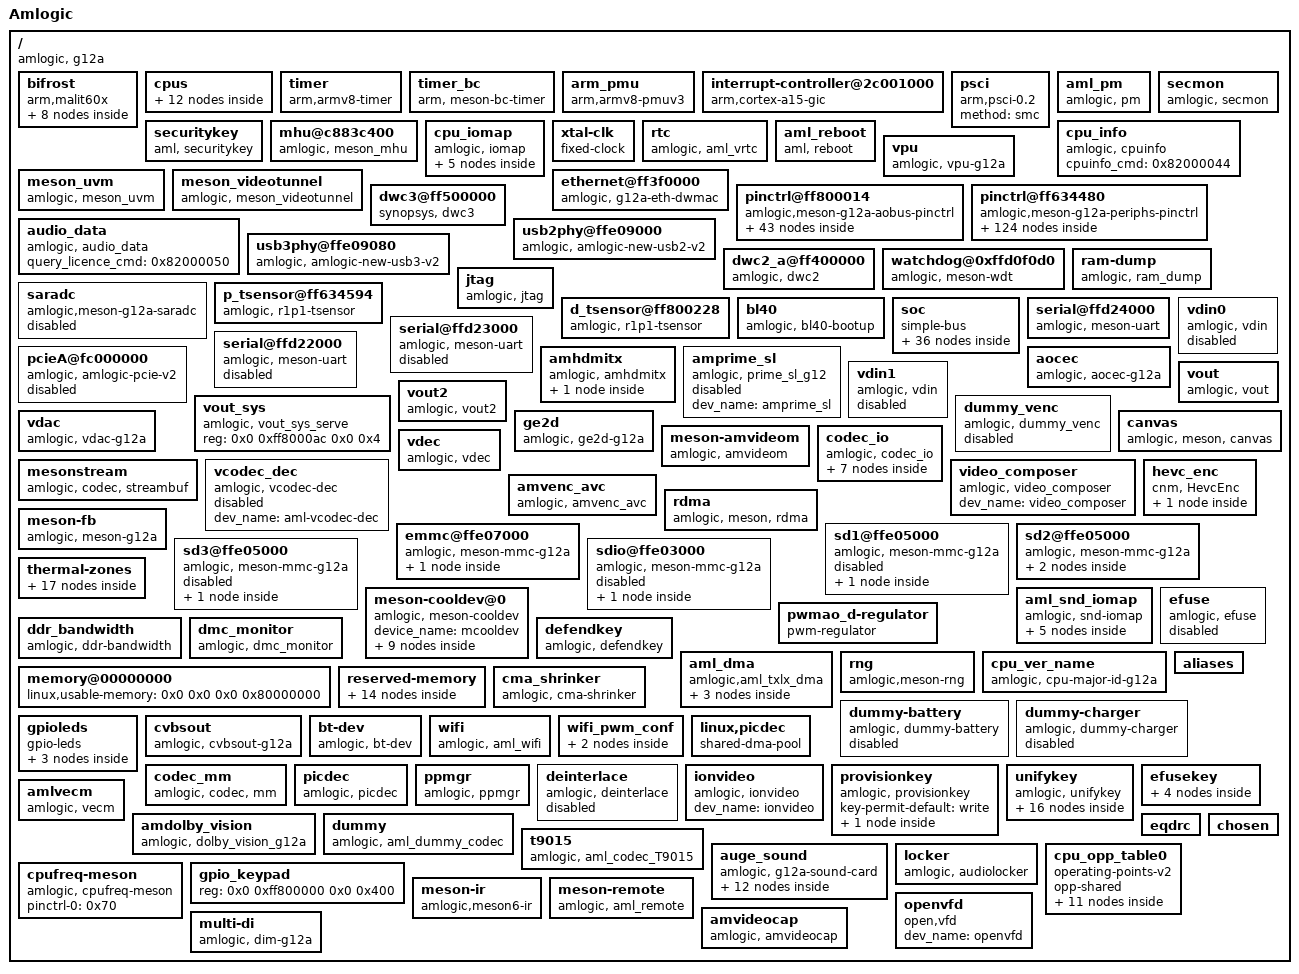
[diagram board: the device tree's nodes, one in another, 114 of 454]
/dts-v1/;

/ {
	model = "Amlogic";
	compatible = "amlogic, g12a";
	interrupt-parent = <0x1>;
	#address-cells = <0x2>;
	#size-cells = <0x2>;
	coreelec;
	coreelec-dt-id = "g12a_s905x2_2g";

	bifrost {
		compatible = "arm,malit60x", "arm,malit6xx", "arm,mali-midgard";
		#cooling-cells = <0x2>;
		reg = <0x0 0xffe40000 0x0 0x4000 0x0 0xffd01000 0x0 0x1000 0x0 0xff800000 0x0 0x1000 0x0 0xff63c000 0x0 0x1000 0x0 0xffd01000 0x0 0x1000>;
		interrupt-parent = <0x1>;
		interrupts = <0x0 0xa0 0x4 0x0 0xa1 0x4 0x0 0xa2 0x4>;
		interrupt-names = "GPU", "MMU", "JOB";
		num_of_pp = <0x2>;
		sc_mpp = <0x1>;
		clocks = <0x2 0x84 0x2 0x7>;
		clock-names = "gpu_mux", "gp0_pll";
		tbl = <0x3 0x4 0x5 0x6 0x7 0x7>;
		phandle = <0x72>;

		clk125_cfg {
			clk_freq = <0x7735940>;
			clk_parent = "fclk_div4";
			clkp_freq = <0x1dcd6500>;
			clk_reg = <0xa03>;
			voltage = <0x47e>;
			keep_count = <0x5>;
			threshold = <0x1e 0x78>;
			phandle = <0x73>;
		};

		dvfs250_cfg {
			clk_freq = <0xee6b280>;
			clk_parent = "fclk_div4";
			clkp_freq = <0x1dcd6500>;
			clk_reg = <0xa01>;
			voltage = <0x47e>;
			keep_count = <0x5>;
			threshold = <0x50 0xaa>;
			phandle = <0x74>;
		};

		dvfs285_cfg {
			clk_freq = <0x1107a76d>;
			clk_parent = "fclk_div7";
			clkp_freq = <0x1107a76d>;
			clk_reg = <0xe00>;
			voltage = <0x47e>;
			keep_count = <0x5>;
			threshold = <0x0 0x4c>;
			phandle = <0x3>;
		};

		dvfs400_cfg {
			clk_freq = <0x17d78400>;
			clk_parent = "fclk_div5";
			clkp_freq = <0x17d78400>;
			clk_reg = <0xc00>;
			voltage = <0x47e>;
			keep_count = <0x5>;
			threshold = <0x98 0xcf>;
			phandle = <0x4>;
		};

		dvfs500_cfg {
			clk_freq = <0x1dcd6500>;
			clk_parent = "fclk_div4";
			clkp_freq = <0x1dcd6500>;
			clk_reg = <0xa00>;
			voltage = <0x47e>;
			keep_count = <0x5>;
			threshold = <0x26 0xc2>;
			phandle = <0x5>;
		};

		dvfs666_cfg {
			clk_freq = <0x27bc86aa>;
			clk_parent = "fclk_div3";
			clkp_freq = <0x27bc86aa>;
			clk_reg = <0x800>;
			voltage = <0x47e>;
			keep_count = <0x5>;
			threshold = <0x96 0xcb>;
			phandle = <0x6>;
		};

		dvfs800_cfg {
			clk_freq = <0x2faf0800>;
			clk_parent = "fclk_div2p5";
			clkp_freq = <0x2faf0800>;
			clk_reg = <0x600>;
			voltage = <0x47e>;
			keep_count = <0x5>;
			threshold = <0xe6 0xff>;
			phandle = <0x75>;
		};

		dvfs850_cfg {
			clk_freq = <0x326cef80>;
			clk_parent = "gp0_pll";
			clkp_freq = <0x326cef80>;
			clk_reg = <0x200>;
			voltage = <0x47e>;
			keep_count = <0x5>;
			threshold = <0x9c 0xff>;
			phandle = <0x7>;
		};
	};

	cpus {
		#address-cells = <0x2>;
		#size-cells = <0x0>;
		phandle = <0x76>;

		cpu-map {

			cluster0 {
				phandle = <0x77>;

				core0 {
					cpu = <0x8>;
				};

				core1 {
					cpu = <0x9>;
				};

				core2 {
					cpu = <0xa>;
				};

				core3 {
					cpu = <0xb>;
				};
			};
		};

		cpu@0 {
			device_type = "cpu";
			compatible = "arm,cortex-a53", "arm,armv8";
			reg = <0x0 0x0>;
			enable-method = "psci";
			cpu-idle-states = <0xc>;
			clocks = <0x2 0x17 0x2 0x16 0x2 0x0>;
			clock-names = "core_clk", "low_freq_clk_parent", "high_freq_clk_parent";
			operating-points-v2 = <0xd>;
			cpu-supply = <0xe>;
			voltage-tolerance = <0x0>;
			clock-latency = <0xc350>;
			phandle = <0x8>;
		};

		cpu@1 {
			device_type = "cpu";
			compatible = "arm,cortex-a53", "arm,armv8";
			reg = <0x0 0x1>;
			enable-method = "psci";
			cpu-idle-states = <0xc>;
			clocks = <0x2 0x17 0x2 0x16 0x2 0x0>;
			clock-names = "core_clk", "low_freq_clk_parent", "high_freq_clk_parent";
			operating-points-v2 = <0xd>;
			cpu-supply = <0xe>;
			voltage-tolerance = <0x0>;
			clock-latency = <0xc350>;
			phandle = <0x9>;
		};

		cpu@2 {
			device_type = "cpu";
			compatible = "arm,cortex-a53", "arm,armv8";
			reg = <0x0 0x2>;
			enable-method = "psci";
			cpu-idle-states = <0xc>;
			clocks = <0x2 0x17 0x2 0x16 0x2 0x0>;
			clock-names = "core_clk", "low_freq_clk_parent", "high_freq_clk_parent";
			operating-points-v2 = <0xd>;
			cpu-supply = <0xe>;
			voltage-tolerance = <0x0>;
			clock-latency = <0xc350>;
			phandle = <0xa>;
		};

		cpu@3 {
			device_type = "cpu";
			compatible = "arm,cortex-a53", "arm,armv8";
			reg = <0x0 0x3>;
			enable-method = "psci";
			cpu-idle-states = <0xc>;
			clocks = <0x2 0x17 0x2 0x16 0x2 0x0>;
			clock-names = "core_clk", "low_freq_clk_parent", "high_freq_clk_parent";
			operating-points-v2 = <0xd>;
			cpu-supply = <0xe>;
			voltage-tolerance = <0x0>;
			clock-latency = <0xc350>;
			phandle = <0xb>;
		};

		idle-states {
			entry-method = "arm,psci-0.2";

			cpu-sleep-0 {
				compatible = "arm,idle-state";
				arm,psci-suspend-param = <0x10000>;
				local-timer-stop;
				entry-latency-us = <0x1388>;
				exit-latency-us = <0x1388>;
				min-residency-us = <0x3a98>;
				phandle = <0xc>;
			};
		};
	};

	timer {
		compatible = "arm,armv8-timer";
		interrupts = <0x1 0xd 0xff08 0x1 0xe 0xff08 0x1 0xb 0xff08 0x1 0xa 0xff08>;
	};

	timer_bc {
		compatible = "arm, meson-bc-timer";
		reg = <0x0 0xffd0f190 0x0 0x4 0x0 0xffd0f194 0x0 0x4>;
		timer_name = "Meson TimerF";
		clockevent-rating = <0x12c>;
		clockevent-shift = <0x14>;
		clockevent-features = <0x23>;
		interrupts = <0x0 0x3c 0x1>;
		bit_enable = <0x10>;
		bit_mode = <0xc>;
		bit_resolution = <0x0>;
	};

	arm_pmu {
		compatible = "arm,armv8-pmuv3";
		interrupts = <0x0 0x89 0x4>;
		reg = <0x0 0xff634680 0x0 0x4>;
		cpumasks = <0xf>;
		relax-timer-ns = <0x989680>;
		max-wait-cnt = <0x2710>;
	};

	interrupt-controller@2c001000 {
		compatible = "arm,cortex-a15-gic", "arm,cortex-a9-gic";
		#interrupt-cells = <0x3>;
		#address-cells = <0x0>;
		interrupt-controller;
		reg = <0x0 0xffc01000 0x0 0x1000 0x0 0xffc02000 0x0 0x100>;
		interrupts = <0x1 0x9 0xf04>;
		phandle = <0x1>;
	};

	psci {
		compatible = "arm,psci-0.2";
		method = "smc";
	};

	aml_pm {
		compatible = "amlogic, pm";
		status = "okay";
		device_name = "aml_pm";
		debug_reg = <0xff8000a8>;
		exit_reg = <0xff80023c>;
	};

	secmon {
		compatible = "amlogic, secmon";
		memory-region = <0xf>;
		in_base_func = <0x82000020>;
		out_base_func = <0x82000021>;
		reserve_mem_size = <0x300000>;
	};

	securitykey {
		compatible = "aml, securitykey";
		storage_query = <0x82000060>;
		storage_read = <0x82000061>;
		storage_write = <0x82000062>;
		storage_tell = <0x82000063>;
		storage_verify = <0x82000064>;
		storage_status = <0x82000065>;
		storage_list = <0x82000067>;
		storage_remove = <0x82000068>;
		storage_in_func = <0x82000023>;
		storage_out_func = <0x82000024>;
		storage_block_func = <0x82000025>;
		storage_size_func = <0x82000027>;
		storage_set_enctype = <0x8200006a>;
		storage_get_enctype = <0x8200006b>;
		storage_version = <0x8200006c>;
	};

	mhu@c883c400 {
		compatible = "amlogic, meson_mhu";
		reg = <0x0 0xff63c400 0x0 0x4c 0x0 0xfffe7000 0x0 0x800>;
		interrupts = <0x0 0xd1 0x1 0x0 0xd2 0x1 0x0 0xd5 0x1>;
		#mbox-cells = <0x1>;
		mbox-names = "cpu_to_scp_low", "bl4_to_cpu", "cpu_to_bl4";
		mboxes = <0x10 0x0 0x10 0x1 0x10 0x2>;
		num-chans-to-scp = <0x1>;
		send-isr-bits = <0x5>;
		ack-isr-bits = <0x4>;
		m4-isr-bits = <0x6>;
		mbox-chans = <0x3>;
		phandle = <0x10>;
	};

	cpu_iomap {
		compatible = "amlogic, iomap";
		#address-cells = <0x2>;
		#size-cells = <0x2>;
		ranges;

		io_cbus_base {
			reg = <0x0 0xffd00000 0x0 0x26000>;
		};

		io_apb_base {
			reg = <0x0 0xffe01000 0x0 0x7f000>;
		};

		io_aobus_base {
			reg = <0x0 0xff800000 0x0 0xb000>;
		};

		io_vapb_base {
			reg = <0x0 0xff900000 0x0 0x50000>;
		};

		io_hiu_base {
			reg = <0x0 0xff63c000 0x0 0x2000>;
		};
	};

	xtal-clk {
		compatible = "fixed-clock";
		clock-frequency = <0x16e3600>;
		clock-output-names = "xtal";
		#clock-cells = <0x0>;
		phandle = <0x15>;
	};

	rtc {
		compatible = "amlogic, aml_vrtc";
		alarm_reg_addr = <0xff8000a8>;
		timer_e_addr = <0xffd0f188>;
		init_date = "2015/01/01";
		status = "okay";
	};

	cpu_info {
		compatible = "amlogic, cpuinfo";
		status = "okay";
		cpuinfo_cmd = <0x82000044>;
	};

	aml_reboot {
		compatible = "aml, reboot";
		sys_reset = <0x84000009>;
		sys_poweroff = <0x84000008>;
	};

	vpu {
		compatible = "amlogic, vpu-g12a";
		dev_name = "vpu";
		status = "okay";
		clocks = <0x2 0x96 0x2 0x4d 0x2 0x88 0x2 0x8c 0x2 0x8d>;
		clock-names = "vapb_clk", "vpu_intr_gate", "vpu_clk0", "vpu_clk1", "vpu_clk";
		clk_level = <0x7>;
	};

	meson_uvm {
		compatible = "amlogic, meson_uvm";
		status = "okay";
	};

	meson_videotunnel {
		compatible = "amlogic, meson_videotunnel";
		status = "okay";
	};

	ethernet@ff3f0000 {
		compatible = "amlogic, g12a-eth-dwmac", "snps,dwmac";
		reg = <0x0 0xff3f0000 0x0 0x10000 0x0 0xff634540 0x0 0x8 0x0 0xff64c000 0x0 0xa0 0x0 0xffd01008 0x0 0x4>;
		reg-names = "eth_base", "eth_cfg", "eth_pll", "eth_reset";
		interrupts = <0x0 0x8 0x1>;
		interrupt-names = "macirq";
		status = "okay";
		clocks = <0x2 0x39>;
		clock-names = "ethclk81";
		pll_val = <0x9c0040a 0x927e0000 0xac5f49e5>;
		analog_val = <0x20200000 0xc000 0x23>;
		pinctrl-names = "internal_eth_pins", "internal_gpio_pins";
		pinctrl-0 = <0x11>;
		pinctrl-1 = <0x12>;
		mc_val = <0x4be04>;
		internal_phy = <0x1>;
		phandle = <0x78>;
	};

	pinctrl@ff800014 {
		compatible = "amlogic,meson-g12a-aobus-pinctrl";
		#address-cells = <0x2>;
		#size-cells = <0x2>;
		ranges;
		phandle = <0x79>;

		ao-bank@ff800014 {
			reg = <0x0 0xff800014 0x0 0x8 0x0 0xff800024 0x0 0x14 0x0 0xff80001c 0x0 0x8>;
			reg-names = "mux", "gpio", "drive-strength";
			gpio-controller;
			#gpio-cells = <0x2>;
			phandle = <0x4c>;
		};

		sd_to_ao_uart_clr_pins {
			phandle = <0x38>;

			mux {
				groups = "GPIOAO_0", "GPIOAO_1";
				function = "gpio_aobus";
			};
		};

		sd_to_ao_uart_pins {
			phandle = <0x3a>;

			mux {
				groups = "uart_ao_tx_a", "uart_ao_rx_a";
				function = "uart_ao_a";
				bias-pull-up;
				input-enable;
			};
		};

		ao_uart {
			phandle = <0x7a>;

			mux {
				groups = "uart_ao_tx_a", "uart_ao_rx_a";
				function = "uart_ao_a";
			};
		};

		ao_b_uart {
			phandle = <0x1b>;

			mux {
				groups = "uart_ao_tx_b_2", "uart_ao_rx_b_3";
				function = "uart_ao_b";
			};
		};

		ao_i2c_pins1 {
			phandle = <0x7b>;

			mux {
				groups = "i2c_ao_sck", "i2c_ao_sda";
				function = "i2c_ao";
				drive-strength = <0x2>;
			};
		};

		ao_i2c_pins2 {
			phandle = <0x7c>;

			mux {
				groups = "i2c_ao_sck_e", "i2c_ao_sda_e";
				function = "i2c_ao";
				drive-strength = <0x2>;
			};
		};

		ao_i2c_slave_pins {
			phandle = <0x1a>;

			mux {
				groups = "i2c_ao_slave_sck", "i2c_ao_slave_sda";
				function = "i2c_ao_slave";
			};
		};

		pwm_ao_a {
			phandle = <0x7d>;

			mux {
				groups = "pwm_ao_a";
				function = "pwm_ao_a";
			};
		};

		pwm_ao_a_hiz {
			phandle = <0x7e>;

			mux {
				groups = "pwm_ao_a_hiz";
				function = "pwm_ao_a";
			};
		};

		pwm_ao_b {
			phandle = <0x7f>;

			mux {
				groups = "pwm_ao_b";
				function = "pwm_ao_b";
			};
		};

		pwm_ao_c_pins1 {
			phandle = <0x80>;

			mux {
				groups = "pwm_ao_c_4";
				function = "pwm_ao_c";
			};
		};

		pwm_ao_c_pins2 {
			phandle = <0x81>;

			mux {
				groups = "pwm_ao_c_6";
				function = "pwm_ao_c";
			};
		};

		pwm_ao_c_hiz {
			phandle = <0x82>;

			mux {
				groups = "pwm_ao_c_hiz_4";
				function = "pwm_ao_c";
			};
		};

		pwm_ao_d_pins1 {
			phandle = <0x83>;

			mux {
				groups = "pwm_ao_d_5";
				function = "pwm_ao_d";
			};
		};

		pwm_ao_d_pins2 {
			phandle = <0x84>;

			mux {
				groups = "pwm_ao_d_10";
				function = "pwm_ao_d";
			};
		};

		pwm_ao_d_pins3 {
			phandle = <0x70>;

			mux {
				groups = "pwm_ao_d_e";
				function = "pwm_ao_d";
			};
		};

		ao_ceca {
			phandle = <0x85>;

			mux {
				groups = "cec_ao_a";
				function = "cec_ao";
			};
		};

		ao_cecb {
			phandle = <0x86>;

			mux {
				groups = "cec_ao_b";
				function = "cec_ao";
			};
		};

		jtag_apao_pin {
			phandle = <0x16>;

			mux {
				groups = "jtag_a_tdi", "jtag_a_tdo", "jtag_a_clk", "jtag_a_tms";
				function = "jtag_a";
			};
		};

		remote_pin {
			phandle = <0x71>;

			mux {
				groups = "remote_input_ao";
				function = "remote_input_ao";
			};
		};

		irblaster_pin {
			phandle = <0x1c>;

			mux {
				groups = "remote_out_ao";
				function = "remote_out_ao";
			};
		};
	};

	pinctrl@ff634480 {
		compatible = "amlogic,meson-g12a-periphs-pinctrl";
		#address-cells = <0x2>;
		#size-cells = <0x2>;
		ranges;
		phandle = <0x87>;

		banks@ff6346c0 {
			reg = <0x0 0xff6346c0 0x0 0x40 0x0 0xff6344e8 0x0 0x18 0x0 0xff634520 0x0 0x18 0x0 0xff634440 0x0 0x4c 0x0 0xff634740 0x0 0x1c>;
			reg-names = "mux", "pull", "pull-enable", "gpio", "drive-strength";
			gpio-controller;
			#gpio-cells = <0x2>;
			phandle = <0x28>;
		};

		emmc_clk_cmd_pins {
			phandle = <0x32>;

			mux {
				groups = "emmc_clk", "emmc_cmd";
				function = "emmc";
				input-enable;
				bias-pull-up;
			};
		};

		emmc_conf_pull_up {
			phandle = <0x33>;

			mux {
				groups = "emmc_nand_d7", "emmc_nand_d6", "emmc_nand_d5", "emmc_nand_d4", "emmc_nand_d3", "emmc_nand_d2", "emmc_nand_d1", "emmc_nand_d0", "emmc_clk", "emmc_cmd";
				function = "emmc";
				input-enable;
				bias-pull-up;
			};
		};

		emmc_conf_pull_done {
			phandle = <0x34>;

			mux {
				groups = "emmc_nand_ds";
				function = "emmc";
				input-enable;
				bias-pull-down;
			};
		};

		sd_clk_cmd_pins {
			phandle = <0x36>;

			mux {
				groups = "sdcard_cmd_c";
				function = "sdcard";
				input-enable;
				bias-pull-up;
				drive-strength = <0x3>;
			};

			mux1 {
				groups = "sdcard_clk_c";
				function = "sdcard";
				bias-pull-up;
				output-high;
				drive-strength = <0x3>;
			};
		};

		sd_all_pins {
			phandle = <0x35>;

			mux {
				groups = "sdcard_d0_c", "sdcard_d1_c", "sdcard_d2_c", "sdcard_d3_c", "sdcard_cmd_c";
				function = "sdcard";
				input-enable;
				bias-pull-up;
				drive-strength = <0x3>;
			};

			mux1 {
				groups = "sdcard_clk_c";
				function = "sdcard";
				bias-pull-up;
				output-high;
				drive-strength = <0x3>;
			};
		};

		sd_1bit_pins {
			phandle = <0x37>;

			mux {
				groups = "sdcard_d0_c", "sdcard_cmd_c";
				function = "sdcard";
				input-enable;
				bias-pull-up;
				drive-strength = <0x3>;
			};

			mux1 {
				groups = "sdcard_clk_c";
				function = "sdcard";
				bias-pull-up;
				output-high;
				drive-strength = <0x3>;
			};
		};

		sd_clr_all_pins {
			phandle = <0x3e>;

			mux {
				groups = "GPIOC_0", "GPIOC_1", "GPIOC_2", "GPIOC_3", "GPIOC_5";
				function = "gpio_periphs";
				output-high;
			};

			mux1 {
				groups = "GPIOC_4";
				function = "gpio_periphs";
				output-low;
			};
		};

		sd_clr_noall_pins {
			phandle = <0x3d>;

			mux {
				groups = "GPIOC_0", "GPIOC_1", "GPIOC_4", "GPIOC_5";
				function = "gpio_periphs";
				output-high;
			};
		};

		ao_to_sd_uart_pins {
			phandle = <0x39>;

			mux {
				groups = "uart_ao_tx_a_c3", "uart_ao_rx_a_c2";
				function = "uart_ao_a_ee";
				bias-pull-up;
				input-enable;
			};
		};

		sdio_clk_cmd_pins {
			phandle = <0x42>;

			mux {
				groups = "sdio_clk", "sdio_cmd";
				function = "sdio";
				input-enable;
				bias-pull-up;
				drive-strength = <0x3>;
			};
		};

		sdio_all_pins {
			phandle = <0x41>;

			mux {
				groups = "sdio_d0", "sdio_d1", "sdio_d2", "sdio_d3", "sdio_clk", "sdio_cmd";
				function = "sdio";
				input-enable;
				bias-pull-up;
				drive-strength = <0x3>;
			};
		};

		sdio_x_clk_cmd_pins {
			phandle = <0x40>;

			mux {
				groups = "GPIOX_5";
				function = "gpio_periphs";
				input-enable;
				bias-pull-up;
				drive-strength = <0x3>;
			};

			mux1 {
				groups = "GPIOX_4";
				function = "gpio_periphs";
				bias-pull-up;
				output-high;
				drive-strength = <0x3>;
			};
		};

		sdio_x_all_pins {
			phandle = <0x3f>;

			mux {
				groups = "GPIOX_0", "GPIOX_1", "GPIOX_2", "GPIOX_3", "GPIOX_5";
				function = "gpio_periphs";
				input-enable;
				bias-pull-up;
				drive-strength = <0x3>;
			};

			mux1 {
				groups = "GPIOX_4";
				function = "gpio_periphs";
				bias-pull-up;
				output-high;
				drive-strength = <0x3>;
			};
		};

		sdio_x_en_pins {
			phandle = <0x3c>;

			mux {
				groups = "sdio_dummy";
				function = "sdio";
				bias-pull-up;
				output-high;
			};
		};

		sdio_x_clr_pins {
			phandle = <0x3b>;

			mux {
				groups = "GPIOV_0";
				function = "gpio_periphs";
				bias-pull-up;
				output-low;
			};

			mux1 {
				groups = "GPIOX_4";
				function = "gpio_periphs";
				output-low;
			};
		};

		all_nand_pins {
			phandle = <0x88>;

			mux {
				groups = "emmc_nand_d0", "emmc_nand_d1", "emmc_nand_d2", "emmc_nand_d3", "emmc_nand_d4", "emmc_nand_d5", "emmc_nand_d6", "emmc_nand_d7", "nand_ce0", "nand_ale", "nand_cle", "nand_wen_clk", "nand_ren_wr", "nand_rb0";
				function = "nand";
				input-enable;
			};
		};

		nand_cs {
			phandle = <0x89>;

			mux {
				groups = "nand_ce0";
				function = "nand";
			};
		};

		i2c0_pins1 {
			phandle = <0x8a>;

			mux {
				groups = "i2c0_sda_c", "i2c0_sck_c";
				function = "i2c0";
				drive-strength = <0x2>;
			};
		};

		i2c0_pins2 {
			phandle = <0x18>;

			mux {
				groups = "i2c0_sda_z0", "i2c0_sck_z1";
				function = "i2c0";
				drive-strength = <0x2>;
			};
		};

		i2c0_pins3 {
			phandle = <0x8b>;

			mux {
				groups = "i2c0_sda_z7", "i2c0_sck_z8";
				function = "i2c0";
				drive-strength = <0x2>;
			};
		};

		i2c1_pins1 {
			phandle = <0x8c>;

			mux {
				groups = "i2c1_sda_x", "i2c1_sck_x";
				function = "i2c1";
				drive-strength = <0x2>;
			};
		};

		i2c1_pins2 {
			phandle = <0x8d>;

			mux {
				groups = "i2c1_sda_h2", "i2c1_sck_h3";
				function = "i2c1";
				drive-strength = <0x2>;
			};
		};

		i2c1_pins3 {
			phandle = <0x8e>;

			mux {
				groups = "i2c1_sda_h6", "i2c1_sck_h7";
				function = "i2c1";
				drive-strength = <0x2>;
			};
		};

		i2c2_pins1 {
			phandle = <0x8f>;

			mux {
				groups = "i2c2_sda_x", "i2c2_sck_x";
				function = "i2c2";
				drive-strength = <0x2>;
			};
		};

		i2c2_pins2 {
			phandle = <0x90>;

			mux {
				groups = "i2c2_sda_z", "i2c2_sck_z";
				function = "i2c2";
				drive-strength = <0x2>;
			};
		};

		i2c3_pins1 {
			phandle = <0x2d>;

			mux {
				groups = "i2c3_sda_h", "i2c3_sck_h";
				function = "i2c3";
				drive-strength = <0x2>;
			};
		};

		i2c3_pins2 {
			phandle = <0x19>;

			mux {
				groups = "i2c3_sda_a", "i2c3_sck_a";
				function = "i2c3";
				drive-strength = <0x2>;
			};
		};

		pwm_a {
			phandle = <0x91>;

			mux {
				groups = "pwm_a";
				function = "pwm_a";
			};
		};

		pwm_b_pins1 {
			phandle = <0x92>;

			mux {
				groups = "pwm_b_x7";
				function = "pwm_b";
			};
		};

		pwm_b_pins2 {
			phandle = <0x93>;

			mux {
				groups = "pwm_b_x19";
				function = "pwm_b";
			};
		};

		pwm_c_pins1 {
			phandle = <0x94>;

			mux {
				groups = "pwm_c_c4";
				function = "pwm_c";
			};
		};

		pwm_c_pins2 {
			phandle = <0x95>;

			mux {
				groups = "pwm_c_x5";
				function = "pwm_c";
			};
		};

		pwm_c_pins3 {
			phandle = <0x96>;

			mux {
				groups = "pwm_c_x8";
				function = "pwm_c";
			};
		};

		pwm_d_pins1 {
			phandle = <0x97>;

			mux {
				groups = "pwm_d_x3";
				function = "pwm_d";
			};
		};

		pwm_d_pins2 {
			phandle = <0x98>;

			mux {
				groups = "pwm_d_x6";
				function = "pwm_d";
			};
		};

		pwm_e {
			phandle = <0x4d>;

			mux {
				groups = "pwm_e";
				function = "pwm_e";
				drive-strength = <0x0>;
			};
		};

		pwm_f_pins1 {
			phandle = <0x99>;

			mux {
				groups = "pwm_f_x";
				function = "pwm_f";
			};
		};

		pwm_f_pins2 {
			phandle = <0x9a>;

			mux {
				groups = "pwm_f_h";
				function = "pwm_f";
			};
		};

		spicc0_pins_x {
			phandle = <0x9b>;

			mux {
				groups = "spi0_mosi_x", "spi0_miso_x", "spi0_clk_x";
				function = "spi0";
				drive-strength = <0x1>;
			};
		};

		spicc0_pins_c {
			phandle = <0x9c>;

			mux {
				groups = "spi0_mosi_c", "spi0_miso_c", "spi0_ss0_c", "spi0_clk_c";
				function = "spi0";
				drive-strength = <0x1>;
			};
		};

		spicc1_pins {
			phandle = <0x9d>;

			mux {
				groups = "spi1_mosi", "spi1_miso", "spi1_clk";
				function = "spi1";
				drive-strength = <0x1>;
			};
		};

		a_uart {
			phandle = <0x25>;

			mux {
				groups = "uart_tx_a", "uart_rx_a", "uart_cts_a", "uart_rts_a";
				function = "uart_a";
			};
		};

		b_uart {
			phandle = <0x26>;

			mux {
				groups = "uart_tx_b", "uart_rx_b";
				function = "uart_b";
			};
		};

		c_uart {
			phandle = <0x27>;

			mux {
				groups = "uart_tx_c", "uart_rx_c";
				function = "uart_c";
			};
		};

		hdmitx_hpd {
			phandle = <0x2a>;

			mux {
				groups = "hdmitx_hpd_in";
				function = "hdmitx";
				bias-disable;
			};
		};

		hdmitx_hpd_gpio {
			phandle = <0x2c>;

			mux {
				groups = "GPIOH_1";
				function = "gpio_periphs";
				bias-disable;
			};
		};

		hdmitx_ddc {
			phandle = <0x2b>;

			mux {
				groups = "hdmitx_sda", "hdmitx_sck";
				function = "hdmitx";
				bias-disable;
				drive-strength = <0x3>;
			};
		};

		ee_ceca {
			phandle = <0x2e>;

			mux {
				groups = "cec_ao_a_ee";
				function = "cec_ao_ee";
			};
		};

		ee_cecb {
			phandle = <0x2f>;

			mux {
				groups = "cec_ao_b_ee";
				function = "cec_ao_ee";
			};
		};

		internal_eth_pins {
			phandle = <0x11>;

			mux {
				groups = "eth_link_led", "eth_act_led";
				function = "eth";
			};
		};

		internal_gpio_pins {
			phandle = <0x12>;

			mux {
				groups = "GPIOZ_14", "GPIOZ_15";
				function = "gpio_periphs";
				bias-disable;
				input-enable;
			};
		};

		external_eth_pins {
			phandle = <0x9e>;

			mux {
				groups = "eth_mdio", "eth_mdc", "eth_rgmii_rx_clk", "eth_rx_dv", "eth_rxd0", "eth_rxd1", "eth_rxd2_rgmii", "eth_rxd3_rgmii", "eth_rgmii_tx_clk", "eth_txen", "eth_txd0", "eth_txd1", "eth_txd2_rgmii", "eth_txd3_rgmii";
				function = "eth";
				drive-strength = <0x3>;
			};
		};

		jtag_apee_pin {
			phandle = <0x17>;

			mux {
				groups = "jtag_b_tdi", "jtag_b_tdo", "jtag_b_clk", "jtag_b_tms";
				function = "jtag_b";
			};
		};

		tdmb_mclk {
			phandle = <0x20>;

			mux {
				groups = "mclk0_a";
				function = "mclk0";
				drive-strength = <0x2>;
			};
		};

		tdmout_b {
			phandle = <0x21>;

			mux {
				groups = "tdmb_sclk", "tdmb_fs", "tdmb_dout0";
				function = "tdmb_out";
				drive-strength = <0x2>;
			};
		};

		tdmin_b {
			phandle = <0x22>;

			mux {
				groups = "tdmb_din1";
				function = "tdmb_in";
				drive-strength = <0x2>;
			};
		};

		spdifout {
			phandle = <0x23>;

			mux {
				groups = "spdif_out_h";
				function = "spdif_out";
			};
		};

		spdifout_a_mute {
			phandle = <0x24>;

			mux {
				groups = "GPIOH_4";
				function = "gpio_periphs";
			};
		};
	};

	audio_data {
		compatible = "amlogic, audio_data";
		query_licence_cmd = <0x82000050>;
		status = "okay";
		phandle = <0x9f>;
	};

	dwc3@ff500000 {
		compatible = "synopsys, dwc3";
		status = "okay";
		reg = <0x0 0xff500000 0x0 0x100000>;
		interrupts = <0x0 0x1e 0x4>;
		usb-phy = <0x13 0x14>;
		cpu-type = "gxl";
		clock-src = "usb3.0";
		clocks = <0x2 0x42>;
		clock-names = "dwc_general";
		phandle = <0xa0>;
	};

	usb2phy@ffe09000 {
		compatible = "amlogic, amlogic-new-usb2-v2";
		status = "okay";
		reg = <0x0 0xffe09000 0x0 0x80 0x0 0xffd01008 0x0 0x100 0x0 0xff636000 0x0 0x2000 0x0 0xff63a000 0x0 0x2000>;
		pll-setting-1 = <0x9400414>;
		pll-setting-2 = <0x927e0000>;
		pll-setting-3 = <0xac5f49e5>;
		pll-setting-4 = <0xfe18>;
		pll-setting-5 = <0x8000fff>;
		pll-setting-6 = <0x78000>;
		pll-setting-7 = <0xe0004>;
		pll-setting-8 = <0xe000c>;
		portnum = <0x2>;
		phandle = <0x13>;
	};

	usb3phy@ffe09080 {
		compatible = "amlogic, amlogic-new-usb3-v2";
		status = "okay";
		reg = <0x0 0xffe09080 0x0 0x20>;
		phy-reg = <0xff646000>;
		phy-reg-size = <0x2000>;
		usb2-phy-reg = <0xffe09000>;
		usb2-phy-reg-size = <0x80>;
		interrupts = <0x0 0x10 0x4>;
		clocks = <0x2 0x18>;
		clock-names = "pcie_refpll";
		portnum = <0x1>;
		otg = <0x0>;
		phandle = <0x14>;
	};

	dwc2_a@ff400000 {
		compatible = "amlogic, dwc2";
		status = "okay";
		device_name = "dwc2_a";
		reg = <0x0 0xff400000 0x0 0x40000>;
		interrupts = <0x0 0x1f 0x4>;
		pl-periph-id = <0x0>;
		clock-src = "usb0";
		port-id = <0x0>;
		port-type = <0x2>;
		port-speed = <0x0>;
		port-config = <0x0>;
		port-dma = <0x0>;
		port-id-mode = <0x0>;
		usb-fifo = <0x2d8>;
		cpu-type = "v2";
		phy-reg = <0xffe09000>;
		phy-reg-size = <0xa0>;
		phy-interface = <0x0>;
		clocks = <0x2 0x42 0x2 0x4a>;
		clock-names = "usb_general", "usb1";
		controller-type = <0x1>;
		phandle = <0xa1>;
	};

	watchdog@0xffd0f0d0 {
		compatible = "amlogic, meson-wdt";
		status = "okay";
		default_timeout = <0xa>;
		reset_watchdog_method = <0x1>;
		reset_watchdog_time = <0x2>;
		shutdown_timeout = <0xa>;
		firmware_timeout = <0x6>;
		suspend_timeout = <0x6>;
		reg = <0x0 0xffd0f0d0 0x0 0x10>;
		clock-names = "xtal";
		clocks = <0x15>;
		phandle = <0xa2>;
	};

	ram-dump {
		compatible = "amlogic, ram_dump";
		status = "okay";
		reg = <0x0 0xff6345e0 0x0 0x4>;
		reg-names = "PREG_STICKY_REG8";
		store_device = "data";
	};

	jtag {
		compatible = "amlogic, jtag";
		status = "okay";
		select = "disable";
		pinctrl-names = "jtag_apao_pins", "jtag_apee_pins";
		pinctrl-0 = <0x16>;
		pinctrl-1 = <0x17>;
	};

	saradc {
		compatible = "amlogic,meson-g12a-saradc";
		status = "disabled";
		#io-channel-cells = <0x1>;
		clocks = <0x15 0x2 0x106>;
		clock-names = "xtal", "saradc_clk";
		interrupts = <0x0 0xc8 0x1>;
		reg = <0x0 0xff809000 0x0 0x48>;
		phandle = <0xa3>;
	};

	p_tsensor@ff634594 {
		compatible = "amlogic, r1p1-tsensor";
		device_name = "meson-pthermal";
		status = "okay";
		reg = <0x0 0xff634800 0x0 0x50 0x0 0xff800268 0x0 0x4>;
		cal_type = <0x1>;
		cal_a = <0x144>;
		cal_b = <0x1a8>;
		cal_c = <0xc57>;
		cal_d = <0x24c3>;
		rtemp = <0x1c138>;
		interrupts = <0x0 0x23 0x0>;
		clocks = <0x2 0xd7>;
		clock-names = "ts_comp";
		#thermal-sensor-cells = <0x1>;
		phandle = <0x43>;
	};

	d_tsensor@ff800228 {
		compatible = "amlogic, r1p1-tsensor";
		device_name = "meson-dthermal";
		status = "okay";
		reg = <0x0 0xff634c00 0x0 0x50 0x0 0xff800230 0x0 0x4>;
		cal_type = <0x1>;
		cal_a = <0x144>;
		cal_b = <0x1a8>;
		cal_c = <0xc57>;
		cal_d = <0x24c3>;
		rtemp = <0x1c138>;
		interrupts = <0x0 0x24 0x0>;
		clocks = <0x2 0xd7>;
		clock-names = "ts_comp";
		#thermal-sensor-cells = <0x1>;
		phandle = <0x49>;
	};

	bl40 {
		compatible = "amlogic, bl40-bootup";
		status = "okay";
		phandle = <0xa4>;
	};

	soc {
		compatible = "simple-bus";
		#address-cells = <0x2>;
		#size-cells = <0x2>;
		ranges;

		cbus@ffd00000 {
			compatible = "simple-bus";
			reg = <0x0 0xffd00000 0x0 0x26000>;
			#address-cells = <0x2>;
			#size-cells = <0x2>;
			ranges = <0x0 0x0 0x0 0xffd00000 0x0 0x26000>;
			phandle = <0xa5>;

			interrupt-controller@f080 {
				compatible = "amlogic,meson-gpio-intc", "amlogic,meson-g12a-gpio-intc";
				reg = <0x0 0xf080 0x0 0x10>;
				interrupt-controller;
				#interrupt-cells = <0x2>;
				amlogic,channel-interrupts = <0x40 0x41 0x42 0x43 0x44 0x45 0x46 0x47>;
				status = "okay";
				phandle = <0xa6>;
			};

			meson_clk_msr {
				compatible = "amlogic, gxl_measure";
				reg = <0x0 0x18004 0x0 0x4 0x0 0x1800c 0x0 0x4>;
				ringctrl = <0xff6345fc>;
			};

			pwm@1b000 {
				compatible = "amlogic,g12a-ee-pwm";
				reg = <0x0 0x1b000 0x0 0x20>;
				#pwm-cells = <0x3>;
				clocks = <0x15 0x15 0x15 0x15>;
				clock-names = "clkin0", "clkin1", "clkin2", "clkin3";
				status = "disabled";
				phandle = <0xa7>;
			};

			pwm@1a000 {
				compatible = "amlogic,g12a-ee-pwm";
				reg = <0x0 0x1a000 0x0 0x20>;
				#pwm-cells = <0x3>;
				clocks = <0x15 0x15 0x15 0x15>;
				clock-names = "clkin0", "clkin1", "clkin2", "clkin3";
				status = "disabled";
				phandle = <0xa8>;
			};

			pwm@19000 {
				compatible = "amlogic,g12a-ee-pwm";
				reg = <0x0 0x19000 0x0 0x20>;
				#pwm-cells = <0x3>;
				clocks = <0x15 0x15 0x15 0x15>;
				clock-names = "clkin0", "clkin1", "clkin2", "clkin3";
				status = "okay";
				phandle = <0x4f>;
			};

			i2c@1f000 {
				compatible = "amlogic,meson-g12a-i2c";
				status = "disabled";
				reg = <0x0 0x1f000 0x0 0x20>;
				interrupts = <0x0 0x15 0x1 0x0 0x5b 0x1>;
				#address-cells = <0x1>;
				#size-cells = <0x0>;
				clocks = <0x2 0x2b>;
				clock-names = "clk_i2c";
				pinctrl-names = "default";
				pinctrl-0 = <0x18>;
				clock-frequency = <0x61a80>;
				phandle = <0xa9>;
			};

			i2c@1e000 {
				compatible = "amlogic,meson-g12a-i2c";
				status = "disabled";
				reg = <0x0 0x1e000 0x0 0x20>;
				interrupts = <0x0 0xd6 0x1 0x0 0x5c 0x1>;
				#address-cells = <0x1>;
				#size-cells = <0x0>;
				clocks = <0x2 0x2b>;
				clock-names = "clk_i2c";
				phandle = <0xaa>;
			};

			i2c@1d000 {
				compatible = "amlogic,meson-g12a-i2c";
				status = "disabled";
				reg = <0x0 0x1d000 0x0 0x20>;
				interrupts = <0x0 0xd7 0x1 0x0 0x5e 0x1>;
				#address-cells = <0x1>;
				#size-cells = <0x0>;
				clocks = <0x2 0x2b>;
				clock-names = "clk_i2c";
				phandle = <0xab>;
			};

			i2c@1c000 {
				compatible = "amlogic,meson-g12a-i2c";
				status = "disabled";
				reg = <0x0 0x1c000 0x0 0x20>;
				interrupts = <0x0 0x27 0x1 0x0 0x5f 0x1>;
				#address-cells = <0x1>;
				#size-cells = <0x0>;
				clocks = <0x2 0x2b>;
				clock-names = "clk_i2c";
				pinctrl-names = "default";
				pinctrl-0 = <0x19>;
				clock-frequency = <0x186a0>;
				phandle = <0xac>;
			};

			spi@13000 {
				compatible = "amlogic,meson-g12a-spicc";
				reg = <0x0 0x13000 0x0 0x44>;
				interrupts = <0x0 0x51 0x4>;
				clocks = <0x2 0x2a 0x2 0xd2>;
				clock-names = "core", "comp";
				#address-cells = <0x1>;
				#size-cells = <0x0>;
				status = "disabled";
				phandle = <0xad>;
			};

			spi@15000 {
				compatible = "amlogic,meson-g12a-spicc";
				reg = <0x0 0x15000 0x0 0x44>;
				interrupts = <0x0 0x5a 0x4>;
				clocks = <0x2 0x30 0x2 0xd6>;
				clock-names = "core", "comp";
				#address-cells = <0x1>;
				#size-cells = <0x0>;
				status = "disabled";
				phandle = <0xae>;
			};
		};

		aobus@ff800000 {
			compatible = "simple-bus";
			reg = <0x0 0xff800000 0x0 0xb000>;
			#address-cells = <0x2>;
			#size-cells = <0x2>;
			ranges = <0x0 0x0 0x0 0xff800000 0x0 0xb000>;
			phandle = <0xaf>;

			cpu_version {
				reg = <0x0 0x220 0x0 0x4>;
			};

			clock-controller@0 {
				compatible = "amlogic,g12a-aoclkc";
				#clock-cells = <0x1>;
				#reset-cells = <0x1>;
				reg = <0x0 0x0 0x0 0x320>;
				phandle = <0xb0>;
			};

			pwm@7000 {
				compatible = "amlogic,g12a-ao-pwm";
				reg = <0x0 0x7000 0x0 0x20>;
				#pwm-cells = <0x3>;
				clocks = <0x15 0x15 0x15 0x15>;
				clock-names = "clkin0", "clkin1", "clkin2", "clkin3";
				status = "disabled";
				phandle = <0xb1>;
			};

			pwm@2000 {
				compatible = "amlogic,g12a-ao-pwm";
				reg = <0x0 0x2000 0x0 0x20>;
				#pwm-cells = <0x3>;
				clocks = <0x15 0x15 0x15 0x15>;
				clock-names = "clkin0", "clkin1", "clkin2", "clkin3";
				status = "okay";
				phandle = <0x4a>;
			};

			i2c@5000 {
				compatible = "amlogic,meson-g12a-i2c";
				status = "disabled";
				reg = <0x0 0x5000 0x0 0x20>;
				interrupts = <0x0 0xc3 0x1 0x0 0xc9 0x1>;
				#address-cells = <0x1>;
				#size-cells = <0x0>;
				clocks = <0x2 0x2b>;
				clock-names = "clk_i2c";
				phandle = <0xb2>;
			};

			i2c_slave@6000 {
				compatible = "amlogic, meson-i2c-slave";
				status = "disabled";
				reg = <0x0 0x6000 0x0 0x20>;
				interrupts = <0x0 0xc2 0x1>;
				pinctrl-names = "default";
				pinctrl-0 = <0x1a>;
				phandle = <0xb3>;
			};

			serial@3000 {
				compatible = "amlogic, meson-uart";
				reg = <0x0 0x3000 0x0 0x18>;
				interrupts = <0x0 0xc1 0x1>;
				status = "okay";
				clocks = <0x15>;
				clock-names = "clk_uart";
				xtal_tick_en = <0x2>;
				fifosize = <0x40>;
				pinctrl-names = "default";
				support-sysrq = <0x0>;
				phandle = <0xb4>;
			};

			serial@4000 {
				compatible = "amlogic, meson-uart";
				reg = <0x0 0x4000 0x0 0x18>;
				interrupts = <0x0 0xc5 0x1>;
				status = "disabled";
				clocks = <0x15>;
				clock-names = "clk_uart";
				fifosize = <0x40>;
				pinctrl-names = "default";
				pinctrl-0 = <0x1b>;
				phandle = <0xb5>;
			};

			meson-irblaster@14c {
				compatible = "amlogic, meson_irblaster";
				reg = <0x0 0x14c 0x0 0x10 0x0 0x40 0x0 0x4>;
				#irblaster-cells = <0x2>;
				pinctrl-names = "default";
				pinctrl-0 = <0x1c>;
				interrupts = <0x0 0xc6 0x1>;
				status = "disabled";
				phandle = <0xb6>;
			};
		};

		periphs@ff634400 {
			compatible = "simple-bus";
			reg = <0x0 0xff634400 0x0 0x400>;
			#address-cells = <0x2>;
			#size-cells = <0x2>;
			ranges = <0x0 0x0 0x0 0xff634400 0x0 0x400>;
			phandle = <0xb7>;
		};

		hiubus@ff63c000 {
			compatible = "simple-bus";
			reg = <0x0 0xff63c000 0x0 0x2000>;
			#address-cells = <0x2>;
			#size-cells = <0x2>;
			ranges = <0x0 0x0 0x0 0xff63c000 0x0 0x2000>;
			phandle = <0xb8>;

			clock-controller@0 {
				compatible = "amlogic,g12a-clkc";
				#clock-cells = <0x1>;
				reg = <0x0 0x0 0x0 0x320>;
				phandle = <0x2>;
			};
		};

		ion_dev {
			compatible = "amlogic, ion_dev";
			memory-region = <0x1d 0x1e>;
		};

		audiobus@0xff642000 {
			compatible = "amlogic, audio-controller", "simple-bus";
			reg = <0x0 0xff642000 0x0 0x2000>;
			#address-cells = <0x2>;
			#size-cells = <0x2>;
			ranges = <0x0 0x0 0x0 0xff642000 0x0 0x2000>;
			phandle = <0xb9>;

			audio_clocks {
				compatible = "amlogic, g12a-audio-clocks";
				#clock-cells = <0x1>;
				reg = <0x0 0x0 0x0 0xb0>;
				phandle = <0x1f>;
			};

			ddr_manager {
				compatible = "amlogic, g12a-audio-ddr-manager";
				interrupts = <0x0 0x94 0x1 0x0 0x95 0x1 0x0 0x96 0x1 0x0 0x98 0x1 0x0 0x99 0x1 0x0 0x9a 0x1>;
				interrupt-names = "toddr_a", "toddr_b", "toddr_c", "frddr_a", "frddr_b", "frddr_c";
			};

			tdmb {
				compatible = "amlogic, g12a-snd-tdmb";
				#sound-dai-cells = <0x0>;
				dai-tdm-lane-slot-mask-in = <0x0 0x1 0x0 0x0>;
				dai-tdm-lane-slot-mask-out = <0x1 0x0 0x0 0x0>;
				dai-tdm-clk-sel = <0x1>;
				clocks = <0x1f 0x18 0x2 0xd 0x2 0xc 0x1f 0x1e>;
				clock-names = "mclk", "clk_srcpll", "samesource_srcpll", "samesource_clk";
				pinctrl-names = "tdm_pins";
				pinctrl-0 = <0x20 0x21 0x22>;
				mclk_pad = <0x0>;
				samesource_sel = <0x3>;
				phandle = <0x6c>;
			};

			i2s2hdmi {
				compatible = "amlogic, g12a-snd-tdmc";
				#sound-dai-cells = <0x0>;
				dai-tdm-lane-slot-mask-out = <0x1 0x1 0x1 0x1>;
				dai-tdm-clk-sel = <0x2>;
				clocks = <0x1f 0x19 0x2 0xe>;
				clock-names = "mclk", "clk_srcpll";
				i2s2hdmi = <0x1>;
				status = "okay";
				phandle = <0x6f>;
			};

			spdif {
				compatible = "amlogic, g12a-snd-spdif-a";
				#sound-dai-cells = <0x0>;
				clocks = <0x2 0xc 0x2 0x4 0x1f 0x10 0x1f 0x11 0x1f 0x1d 0x1f 0x1e>;
				clock-names = "sysclk", "fixed_clk", "gate_spdifin", "gate_spdifout", "clk_spdifin", "clk_spdifout";
				interrupts = <0x0 0x97 0x1>;
				interrupt-names = "irq_spdifin";
				pinctrl-names = "spdif_pins", "spdif_pins_mute";
				pinctrl-0 = <0x23>;
				pinctrl-1 = <0x24>;
				status = "okay";
				phandle = <0x6e>;
			};

			spdif_b {
				compatible = "amlogic, g12a-snd-spdif-b";
				#sound-dai-cells = <0x0>;
				clocks = <0x2 0xc 0x1f 0x15 0x1f 0x21>;
				clock-names = "sysclk", "gate_spdifout", "clk_spdifout";
				status = "okay";
				phandle = <0x6a>;
			};

			loopback@0 {
				compatible = "amlogic, g12a-loopback";
				#sound-dai-cells = <0x0>;
				clocks = <0x1f 0x1 0x2 0x3 0x2 0xf 0x1f 0x1f 0x1f 0x20 0x2 0xc 0x1f 0x17>;
				clock-names = "pdm_gate", "pdm_sysclk_srcpll", "pdm_dclk_srcpll", "pdm_dclk", "pdm_sysclk", "tdminlb_mpll", "tdminlb_mclk";
				datain_src = <0x4>;
				datain_chnum = <0x4>;
				datain_chmask = <0xf>;
				datain-lane-mask-in = <0x1 0x0 0x1 0x0>;
				mclk-fs = <0x100>;
				datalb_src = <0x1>;
				datalb_chnum = <0x2>;
				datalb_chmask = <0x3>;
				datalb-lane-mask-in = <0x1 0x0 0x0 0x0>;
				status = "okay";
				phandle = <0xba>;
			};

			resample {
				compatible = "amlogic, g12a-resample";
				clocks = <0x2 0xf 0x1f 0x1c 0x1f 0x24>;
				clock-names = "resample_pll", "resample_src", "resample_clk";
				resample_module = <0x4>;
				status = "okay";
				phandle = <0xbb>;
			};

			pwrdet {
				compatible = "amlogic, g12a-power-detect";
				interrupts = <0x0 0x9b 0x1>;
				interrupt-names = "pwrdet_irq";
				pwrdet_src = <0x4>;
				hi_th = <0x70000>;
				lo_th = <0x16000>;
				status = "disabled";
				phandle = <0xbc>;
			};
		};
	};

	serial@ffd24000 {
		compatible = "amlogic, meson-uart";
		reg = <0x0 0xffd24000 0x0 0x18>;
		interrupts = <0x0 0x1a 0x1>;
		status = "okay";
		clocks = <0x15 0x2 0x2f>;
		clock-names = "clk_uart", "clk_gate";
		fifosize = <0x80>;
		pinctrl-names = "default";
		pinctrl-0 = <0x25>;
		phandle = <0xbd>;
	};

	serial@ffd23000 {
		compatible = "amlogic, meson-uart";
		reg = <0x0 0xffd23000 0x0 0x18>;
		interrupts = <0x0 0x4b 0x1>;
		status = "disabled";
		clocks = <0x15 0x2 0x3d>;
		clock-names = "clk_uart", "clk_gate";
		fifosize = <0x40>;
		pinctrl-names = "default";
		pinctrl-0 = <0x26>;
		phandle = <0xbe>;
	};

	serial@ffd22000 {
		compatible = "amlogic, meson-uart";
		reg = <0x0 0xffd22000 0x0 0x18>;
		interrupts = <0x0 0x5d 0x1>;
		status = "disabled";
		clocks = <0x15 0x2 0x3d>;
		clock-names = "clk_uart", "clk_gate";
		fifosize = <0x40>;
		pinctrl-names = "default";
		pinctrl-0 = <0x27>;
		phandle = <0xbf>;
	};

	pcieA@fc000000 {
		compatible = "amlogic, amlogic-pcie-v2", "snps,dw-pcie";
		reg = <0x0 0xfc000000 0x0 0x400000 0x0 0xff648000 0x0 0x2000 0x0 0xfc400000 0x0 0x200000 0x0 0xff646000 0x0 0x2000 0x0 0xffd01080 0x0 0x10>;
		reg-names = "elbi", "cfg", "config", "phy", "reset";
		interrupts = <0x0 0xdd 0x0>;
		#interrupt-cells = <0x1>;
		bus-range = <0x0 0xff>;
		#address-cells = <0x3>;
		#size-cells = <0x2>;
		interrupt-map-mask = <0x0 0x0 0x0 0x0>;
		interrupt-map = <0x0 0x0 0x0 0x0 0x1 0x0 0xdf 0x1>;
		device_type = "pci";
		ranges = <0x81000000 0x0 0x0 0x0 0xfc600000 0x0 0x100000 0x82000000 0x0 0xfc700000 0x0 0xfc700000 0x0 0x1900000>;
		num-lanes = <0x1>;
		pcie-num = <0x1>;
		clocks = <0x2 0x18 0x2 0x40 0x2 0x43 0x2 0x21>;
		clock-names = "pcie_refpll", "pcie", "pcie_phy", "pcie_hcsl";
		gpio-type = <0x2>;
		pcie-apb-rst-bit = <0xf>;
		pcie-phy-rst-bit = <0xe>;
		pcie-ctrl-a-rst-bit = <0xc>;
		status = "disabled";
		reset-gpio = <0x28 0x49 0x0>;
		phandle = <0xc0>;
	};

	amhdmitx {
		compatible = "amlogic, amhdmitx";
		dev_name = "amhdmitx";
		status = "okay";
		vend-data = <0x29>;
		pinctrl-names = "default", "hdmitx_i2c";
		pinctrl-0 = <0x2a 0x2b>;
		pinctrl-1 = <0x2c 0x2d>;
		clocks = <0x2 0x56 0x2 0x4f 0x2 0x50 0x2 0x96 0x2 0x8d>;
		clock-names = "venci_top_gate", "venci_0_gate", "venci_1_gate", "hdmi_vapb_clk", "hdmi_vpu_clk";
		interrupts = <0x0 0x39 0x1 0x0 0x3 0x1>;
		interrupt-names = "hdmitx_hpd", "viu1_vsync";
		ic_type = <0xa>;
		dongle_mode = <0x0>;
		phandle = <0xc1>;

		vend_data {
			vendor_name = "Amlogic";
			product_desc = "MBox Meson Ref";
			vendor_id = <0x0>;
			phandle = <0x29>;
		};
	};

	amprime_sl {
		compatible = "amlogic, prime_sl_g12";
		dev_name = "amprime_sl";
		status = "disabled";
		phandle = <0xc2>;
	};

	aocec {
		compatible = "amlogic, aocec-g12a";
		device_name = "aocec";
		status = "okay";
		vendor_name = "Amlogic";
		vendor_id = <0x0>;
		product_desc = "G12A";
		cec_osd_string = "AML_MBOX";
		cec_version = <0x5>;
		port_num = <0x1>;
		output = <0x1>;
		ee_cec;
		interrupts = <0x0 0xcb 0x1 0x0 0xc7 0x1>;
		interrupt-names = "hdmi_aocecb", "hdmi_aocec";
		pinctrl-names = "default", "hdmitx_aocecb", "cec_pin_sleep";
		pinctrl-0 = <0x2e>;
		pinctrl-1 = <0x2f>;
		pinctrl-2 = <0x2f>;
		reg = <0x0 0xff80023c 0x0 0x4 0x0 0xff800000 0x0 0x400 0x0 0xff634400 0x0 0x26>;
		reg-names = "ao_exit", "ao", "periphs";
		phandle = <0xc3>;
	};

	vdin0 {
		compatible = "amlogic, vdin";
		dev_name = "vdin0";
		status = "disabled";
		reserve-iomap = "true";
		flag_cma = <0x0>;
		interrupts = <0x0 0x53 0x1>;
		rdma-irq = <0x2>;
		vdin_id = <0x0>;
		cma_size = <0x14>;
		tv_bit_mode = <0x1>;
		phandle = <0xc4>;
	};

	vdin1 {
		compatible = "amlogic, vdin";
		dev_name = "vdin1";
		status = "disabled";
		reserve-iomap = "true";
		flag_cma = <0x0>;
		interrupts = <0x0 0x55 0x1>;
		rdma-irq = <0x4>;
		vdin_id = <0x1>;
		memory-region = <0x30>;
		tv_bit_mode = <0x1>;
		phandle = <0xc5>;
	};

	vout_sys {
		compatible = "amlogic, vout_sys_serve";
		status = "okay";
		reg = <0x0 0xff8000ac 0x0 0x4>;
		phandle = <0xc6>;
	};

	vout {
		compatible = "amlogic, vout";
		dev_name = "vout";
		status = "okay";
		fr_policy = <0x0>;
	};

	vout2 {
		compatible = "amlogic, vout2";
		dev_name = "vout";
		status = "okay";
		clocks = <0x2 0xc5 0x2 0xca>;
		clock-names = "vpu_clkc0", "vpu_clkc";
		fr_policy = <0x0>;
	};

	dummy_venc {
		compatible = "amlogic, dummy_venc";
		status = "disabled";
		clocks = <0x2 0x57 0x2 0x51 0x2 0x52 0x2 0x56 0x2 0x4f 0x2 0x50 0x2 0x5e 0x2 0x60>;
		clock-names = "encp_top_gate", "encp_int_gate0", "encp_int_gate1", "venci_top_gate", "enci_int_gate0", "enci_int_gate1", "encl_top_gate", "encl_int_gate";
		phandle = <0xc7>;
	};

	vdac {
		compatible = "amlogic, vdac-g12a";
		status = "okay";
	};

	canvas {
		compatible = "amlogic, meson, canvas";
		dev_name = "amlogic-canvas";
		status = "okay";
		reg = <0x0 0xff638000 0x0 0x2000>;
		phandle = <0xc8>;
	};

	ge2d {
		compatible = "amlogic, ge2d-g12a";
		dev_name = "ge2d";
		status = "okay";
		interrupts = <0x0 0x92 0x1>;
		interrupt-names = "ge2d";
		clocks = <0x2 0x96 0x2 0x3e 0x2 0x97>;
		clock-names = "clk_vapb_0", "clk_ge2d", "clk_ge2d_gate";
		reg = <0x0 0xff940000 0x0 0x10000>;
	};

	meson-amvideom {
		compatible = "amlogic, amvideom";
		dev_name = "amvideom";
		status = "okay";
		interrupts = <0x0 0x3 0x1>;
		interrupt-names = "vsync";
	};

	codec_io {
		compatible = "amlogic, codec_io";
		status = "okay";
		#address-cells = <0x2>;
		#size-cells = <0x2>;
		ranges;
		phandle = <0xc9>;

		io_cbus_base {
			reg = <0x0 0xffd00000 0x0 0x100000>;
		};

		io_dos_base {
			reg = <0x0 0xff620000 0x0 0x10000>;
		};

		io_hiubus_base {
			reg = <0x0 0xff63c000 0x0 0x2000>;
		};

		io_aobus_base {
			reg = <0x0 0xff800000 0x0 0x10000>;
		};

		io_vcbus_base {
			reg = <0x0 0xff900000 0x0 0x40000>;
		};

		io_dmc_base {
			reg = <0x0 0xff638000 0x0 0x2000>;
		};

		io_efuse_base {
			reg = <0x0 0xff630000 0x0 0x2000>;
		};
	};

	mesonstream {
		compatible = "amlogic, codec, streambuf";
		dev_name = "mesonstream";
		status = "okay";
		clocks = <0x2 0x41 0x2 0x3a 0x2 0x44 0x2 0x23 0x2 0xb 0x2 0xa6 0x2 0xaf 0x2 0xb8 0x2 0xc1>;
		clock-names = "parser_top", "demux", "ahbarb0", "vdec", "clk_81", "clk_vdec_mux", "clk_hcodec_mux", "clk_hevc_mux", "clk_hevcb_mux";
	};

	vdec {
		compatible = "amlogic, vdec";
		dev_name = "vdec.0";
		status = "okay";
		interrupts = <0x0 0x3 0x1 0x0 0x17 0x1 0x0 0x20 0x1 0x0 0x2b 0x1 0x0 0x2c 0x1 0x0 0x2d 0x1>;
		interrupt-names = "vsync", "demux", "parser", "mailbox_0", "mailbox_1", "mailbox_2";
	};

	vcodec_dec {
		compatible = "amlogic, vcodec-dec";
		dev_name = "aml-vcodec-dec";
		status = "disable";
	};

	video_composer {
		compatible = "amlogic, video_composer";
		dev_name = "video_composer";
		status = "okay";
	};

	amvenc_avc {
		compatible = "amlogic, amvenc_avc";
		dev_name = "amvenc_avc";
		status = "okay";
		interrupts = <0x0 0x2d 0x1>;
		interrupt-names = "mailbox_2";
	};

	hevc_enc {
		compatible = "cnm, HevcEnc";
		dev_name = "HevcEnc";
		status = "okay";
		interrupts = <0x0 0xbb 0x1>;
		interrupt-names = "wave420l_irq";
		#address-cells = <0x2>;
		#size-cells = <0x2>;
		ranges;

		io_reg_base {
			reg = <0x0 0xff610000 0x0 0x4000>;
		};
	};

	rdma {
		compatible = "amlogic, meson, rdma";
		dev_name = "amlogic-rdma";
		status = "okay";
		interrupts = <0x0 0x59 0x1>;
		interrupt-names = "rdma";
	};

	meson-fb {
		compatible = "amlogic, meson-g12a";
		memory-region = <0x31>;
		dev_name = "meson-fb";
		status = "okay";
		interrupts = <0x0 0x3 0x1 0x0 0x38 0x1 0x0 0x59 0x1>;
		interrupt-names = "viu-vsync", "viu2-vsync", "rdma";
		display_mode_default = "1080p60hz";
		scale_mode = <0x1>;
		display_size_default = <0x780 0x438 0x780 0x870 0x20>;
		clocks = <0x2 0xca>;
		clock-names = "vpu_clkc";
		mem_size = <0x800000 0x4b80000 0x100000 0x100000 0x800000>;
		logo_addr = "0x7f800000";
		mem_alloc = <0x1>;
		pxp_mode = <0x0>;
		4k2k_fb = <0x1>;
		phandle = <0xca>;
	};

	emmc@ffe07000 {
		status = "okay";
		compatible = "amlogic, meson-mmc-g12a";
		reg = <0x0 0xffe07000 0x0 0x800>;
		interrupts = <0x0 0xbf 0x1>;
		pinctrl-names = "emmc_clk_cmd_pins", "emmc_all_pins";
		pinctrl-0 = <0x32>;
		pinctrl-1 = <0x33 0x34>;
		clocks = <0x2 0x36 0x2 0x73 0x2 0x2 0x2 0x5 0x15>;
		clock-names = "core", "clkin0", "clkin1", "clkin2", "xtal";
		bus-width = <0x8>;
		cap-sd-highspeed;
		cap-mmc-highspeed;
		max-frequency = <0x5f5e100>;
		non-removable;
		disable-wp;
		phandle = <0xcb>;

		emmc {
			pinname = "emmc";
			ocr_avail = <0x200080>;
			tx_delay = <0x0>;
			co_phase = <0x3>;
			calc_f = <0x1>;
			max_req_size = <0x20000>;
			gpio_dat3 = <0x28 0x1d 0x0>;
			hw_reset = <0x28 0x26 0x0>;
			card_type = <0x1>;
			caps = "MMC_CAP_8_BIT_DATA", "MMC_CAP_MMC_HIGHSPEED", "MMC_CAP_SD_HIGHSPEED", "MMC_CAP_NONREMOVABLE", "MMC_CAP_HW_RESET", "MMC_CAP_ERASE", "MMC_CAP_CMD23";
			caps2 = "MMC_CAP2_HS200";
			f_min = <0x61a80>;
			f_max = <0xa21fe80>;
		};
	};

	sd1@ffe05000 {
		status = "disabled";
		compatible = "amlogic, meson-mmc-g12a";
		reg = <0x0 0xffe05000 0x0 0x800>;
		interrupts = <0x0 0xbe 0x1>;
		pinctrl-names = "sd_all_pins", "sd_clk_cmd_pins", "sd_1bit_pins", "sd_clk_cmd_uart_pins", "sd_1bit_uart_pins", "sd_to_ao_uart_pins", "ao_to_sd_uart_pins", "sd_to_ao_jtag_pins", "ao_to_sd_jtag_pins";
		pinctrl-0 = <0x35>;
		pinctrl-1 = <0x36>;
		pinctrl-2 = <0x37>;
		pinctrl-3 = <0x38 0x36 0x39>;
		pinctrl-4 = <0x38 0x37 0x39>;
		pinctrl-5 = <0x35 0x3a>;
		pinctrl-6 = <0x38 0x39>;
		pinctrl-7 = <0x35 0x3a>;
		pinctrl-8 = <0x38 0x39>;
		clocks = <0x2 0x35 0x2 0x6f 0x2 0x2 0x2 0x5 0x15>;
		clock-names = "core", "clkin0", "clkin1", "clkin2", "xtal";
		bus-width = <0x4>;
		cap-sd-highspeed;
		cap-mmc-highspeed;
		max-frequency = <0x5f5e100>;
		disable-wp;
		phandle = <0xcc>;

		sd {
			pinname = "sd";
			ocr_avail = <0x200080>;
			max_req_size = <0x20000>;
			gpio_dat3 = <0x28 0x2d 0x0>;
			jtag_pin = <0x28 0x2a 0x0>;
			gpio_cd = <0x28 0x30 0x0>;
			card_type = <0x5>;
			caps = "MMC_CAP_4_BIT_DATA", "MMC_CAP_MMC_HIGHSPEED", "MMC_CAP_SD_HIGHSPEED";
			f_min = <0x61a80>;
			f_max = <0x2faf080>;
		};
	};

	sd2@ffe05000 {
		status = "okay";
		compatible = "amlogic, meson-mmc-g12a";
		reg = <0x0 0xffe05000 0x0 0x800>;
		interrupts = <0x0 0xbe 0x4>;
		pinctrl-names = "sd_all_pins", "sd_clk_cmd_pins", "sd_1bit_pins", "sd_clk_cmd_uart_pins", "sd_1bit_uart_pins", "sd_to_ao_uart_pins", "ao_to_sd_uart_pins", "sd_to_ao_jtag_pins", "ao_to_sd_jtag_pins", "sdio_noclr_all_pins", "sdio_noclr_clk_cmd_pins", "sdio_all_pins", "sdio_clk_cmd_pins";
		pinctrl-0 = <0x3b 0x35>;
		pinctrl-1 = <0x3b 0x36>;
		pinctrl-2 = <0x3b 0x37>;
		pinctrl-3 = <0x3b 0x38 0x36 0x39>;
		pinctrl-4 = <0x3b 0x38 0x37 0x39>;
		pinctrl-5 = <0x3b 0x35 0x3a>;
		pinctrl-6 = <0x3c 0x38 0x3d 0x39>;
		pinctrl-7 = <0x3c 0x3e 0x3a>;
		pinctrl-8 = <0x3c 0x38 0x3d 0x39>;
		pinctrl-9 = <0x3d 0x3c 0x3f>;
		pinctrl-10 = <0x3d 0x3c 0x40>;
		pinctrl-11 = <0x3e 0x3c 0x3f>;
		pinctrl-12 = <0x3e 0x3c 0x40>;
		clocks = <0x2 0x35 0x2 0x6f 0x2 0x2 0x2 0x5 0x15>;
		clock-names = "core", "clkin0", "clkin1", "clkin2", "xtal";
		bus-width = <0x4>;
		cap-sd-highspeed;
		cap-mmc-highspeed;
		max-frequency = <0x5f5e100>;
		disable-wp;
		phandle = <0xcd>;

		sd {
			pinname = "sd";
			ocr_avail = <0x200080>;
			max_req_size = <0x20000>;
			gpio_dat3 = <0x28 0x2d 0x0>;
			jtag_pin = <0x28 0x2a 0x0>;
			gpio_cd = <0x28 0x30 0x0>;
			card_type = <0x5>;
			caps = "MMC_CAP_4_BIT_DATA", "MMC_CAP_MMC_HIGHSPEED", "MMC_CAP_SD_HIGHSPEED";
			f_min = <0x61a80>;
			f_max = <0x2faf080>;
		};

		sdio {
			pinname = "sdio";
			ocr_avail = <0x200080>;
			max_req_size = <0x20000>;
			card_type = <0x3>;
			caps = "MMC_CAP_4_BIT_DATA", "MMC_CAP_MMC_HIGHSPEED", "MMC_CAP_SD_HIGHSPEED", "MMC_CAP_NONREMOVABLE", "MMC_CAP_UHS_SDR12", "MMC_CAP_UHS_SDR25", "MMC_CAP_UHS_SDR50", "MMC_CAP_UHS_SDR104", "MMC_PM_KEEP_POWER", "MMC_CAP_SDIO_IRQ";
			f_min = <0x61a80>;
			f_max = <0x5f5e100>;
		};
	};

	sd3@ffe05000 {
		status = "disabled";
		compatible = "amlogic, meson-mmc-g12a";
		reg = <0x0 0xffe05000 0x0 0x800>;
		interrupts = <0x0 0xbe 0x4>;
		pinctrl-names = "sdio_all_pins", "sdio_clk_cmd_pins";
		pinctrl-0 = <0x3c 0x3f>;
		pinctrl-1 = <0x3c 0x40>;
		clocks = <0x2 0x35 0x2 0x6f 0x2 0x2 0x2 0x5 0x15>;
		clock-names = "core", "clkin0", "clkin1", "clkin2", "xtal";
		bus-width = <0x4>;
		cap-sd-highspeed;
		cap-mmc-highspeed;
		max-frequency = <0x5f5e100>;
		disable-wp;
		phandle = <0xce>;

		sdio {
			pinname = "sdio";
			ocr_avail = <0x200080>;
			max_req_size = <0x20000>;
			card_type = <0x3>;
		};
	};

	sdio@ffe03000 {
		status = "disabled";
		compatible = "amlogic, meson-mmc-g12a";
		reg = <0x0 0xffe03000 0x0 0x800>;
		interrupts = <0x0 0xbd 0x4>;
		pinctrl-names = "sdio_all_pins", "sdio_clk_cmd_pins";
		pinctrl-0 = <0x41>;
		pinctrl-1 = <0x42>;
		clocks = <0x2 0x34 0x2 0x6b 0x2 0x2 0x2 0x5 0x15>;
		clock-names = "core", "clkin0", "clkin1", "clkin2", "xtal";
		bus-width = <0x4>;
		cap-sd-highspeed;
		cap-mmc-highspeed;
		max-frequency = <0xa21fe80>;
		disable-wp;
		phandle = <0xcf>;

		sdio {
			pinname = "sdio";
			ocr_avail = <0x200080>;
			max_req_size = <0x400>;
			card_type = <0x3>;
			dmode = "pio";
			caps = "MMC_CAP_4_BIT_DATA", "MMC_CAP_MMC_HIGHSPEED", "MMC_CAP_SD_HIGHSPEED", "MMC_CAP_NONREMOVABLE", "MMC_CAP_UHS_SDR12", "MMC_CAP_UHS_SDR25", "MMC_CAP_UHS_SDR50", "MMC_CAP_UHS_SDR104", "MMC_PM_KEEP_POWER", "MMC_CAP_SDIO_IRQ";
			f_min = <0x61a80>;
			f_max = <0xa21fe80>;
		};
	};

	meson-cooldev@0 {
		status = "okay";
		compatible = "amlogic, meson-cooldev";
		device_name = "mcooldev";
		phandle = <0xd0>;

		cooling_devices {

			cpufreq_cool_cluster0 {
				min_state = <0xf4240>;
				dyn_coeff = <0x73>;
				cluster_id = <0x0>;
				node_name = "cpufreq_cool0";
				device_type = "cpufreq";
			};

			cpucore_cool_cluster0 {
				min_state = <0x1>;
				dyn_coeff = <0x0>;
				cluster_id = <0x0>;
				node_name = "cpucore_cool0";
				device_type = "cpucore";
			};

			gpufreq_cool {
				min_state = <0x190>;
				dyn_coeff = <0x166>;
				gpu_pp = <0x2>;
				cluster_id = <0x0>;
				node_name = "gpufreq_cool0";
				device_type = "gpufreq";
			};

			gpucore_cool {
				min_state = <0x1>;
				dyn_coeff = <0x0>;
				cluster_id = <0x0>;
				node_name = "gpucore_cool0";
				device_type = "gpucore";
			};
		};

		cpufreq_cool0 {
			#cooling-cells = <0x2>;
			phandle = <0x45>;
		};

		cpucore_cool0 {
			#cooling-cells = <0x2>;
			phandle = <0x46>;
		};

		gpufreq_cool0 {
			#cooling-cells = <0x2>;
			phandle = <0x47>;
		};

		gpucore_cool0 {
			#cooling-cells = <0x2>;
			phandle = <0x48>;
		};
	};

	thermal-zones {

		soc_thermal {
			polling-delay = <0x3e8>;
			polling-delay-passive = <0x64>;
			sustainable-power = <0x5b4>;
			thermal-sensors = <0x43 0x0>;
			phandle = <0xd1>;

			trips {

				trip-point@0 {
					temperature = <0xea60>;
					hysteresis = <0x1388>;
					type = "passive";
					phandle = <0xd2>;
				};

				trip-point@1 {
					temperature = <0x124f8>;
					hysteresis = <0x1388>;
					type = "passive";
					phandle = <0x44>;
				};

				trip-point@2 {
					temperature = <0x14c08>;
					hysteresis = <0x1388>;
					type = "hot";
					phandle = <0xd3>;
				};

				trip-point@3 {
					temperature = <0x1adb0>;
					hysteresis = <0x3e8>;
					type = "critical";
					phandle = <0xd4>;
				};
			};

			cooling-maps {

				cpufreq_cooling_map {
					trip = <0x44>;
					cooling-device = <0x45 0x0 0x4>;
					contribution = <0x400>;
				};

				cpucore_cooling_map {
					trip = <0x44>;
					cooling-device = <0x46 0x0 0x3>;
					contribution = <0x400>;
				};

				gpufreq_cooling_map {
					trip = <0x44>;
					cooling-device = <0x47 0x0 0x4>;
					contribution = <0x400>;
				};

				gpucore_cooling_map {
					trip = <0x44>;
					cooling-device = <0x48 0x0 0x2>;
					contribution = <0x400>;
				};
			};
		};

		ddr_thermal {
			polling-delay = <0x3e8>;
			polling-delay-passive = <0x64>;
			sustainable-power = <0x866>;
			thermal-sensors = <0x49 0x1>;
			phandle = <0xd5>;

			trips {

				trip-point@0 {
					temperature = <0xea60>;
					hysteresis = <0x1388>;
					type = "passive";
					phandle = <0xd6>;
				};

				trip-point@1 {
					temperature = <0x124f8>;
					hysteresis = <0x1388>;
					type = "passive";
					phandle = <0xd7>;
				};

				trip-point@2 {
					temperature = <0x14c08>;
					hysteresis = <0x1388>;
					type = "hot";
					phandle = <0xd8>;
				};

				trip-point@3 {
					temperature = <0x1adb0>;
					hysteresis = <0x3e8>;
					type = "critical";
					phandle = <0xd9>;
				};
			};
		};
	};

	aml_snd_iomap {
		compatible = "amlogic, snd-iomap";
		status = "okay";
		#address-cells = <0x2>;
		#size-cells = <0x2>;
		ranges;

		pdm_bus {
			reg = <0x0 0xff640000 0x0 0x2000>;
		};

		audiobus_base {
			reg = <0x0 0xff642000 0x0 0x2000>;
		};

		audiolocker_base {
			reg = <0x0 0xff64a000 0x0 0x2000>;
		};

		eqdrc_base {
			reg = <0x0 0xff642800 0x0 0x1800>;
		};

		reset_base {
			reg = <0x0 0xffd01000 0x0 0x1000>;
		};
	};

	pwmao_d-regulator {
		compatible = "pwm-regulator";
		pwms = <0x4a 0x1 0x4e2 0x0>;
		regulator-name = "vddcpu0";
		regulator-min-microvolt = <0xb0068>;
		regulator-max-microvolt = <0xf9830>;
		regulator-always-on;
		max-duty-cycle = <0x4e2>;
		voltage-table = <0xf9830 0x0 0xf6d38 0x3 0xf4628 0x6 0xf1f18 0xa 0xef808 0xd 0xed0f8 0x10 0xea9e8 0x14 0xe82d8 0x17 0xe5bc8 0x1a 0xe34b8 0x1e 0xe0da8 0x21 0xde698 0x24 0xdbf88 0x28 0xd9878 0x2b 0xd7168 0x2e 0xd4a58 0x32 0xd2348 0x35 0xcfc38 0x38 0xcd528 0x3c 0xcae18 0x3f 0xc8708 0x43 0xc5ff8 0x46 0xc38e8 0x49 0xc11d8 0x4c 0xbeac8 0x50 0xbc3b8 0x53 0xb9ca8 0x56 0xb7598 0x5a 0xb4e88 0x5d 0xb2778 0x60 0xb0068 0x64>;
		status = "okay";
		phandle = <0xe>;
	};

	ddr_bandwidth {
		compatible = "amlogic, ddr-bandwidth";
		status = "okay";
		reg = <0x0 0xff638000 0x0 0x100 0x0 0xff638c00 0x0 0x100>;
		sec_base = <0xff639000>;
		interrupts = <0x0 0x34 0x1>;
		interrupt-names = "ddr_bandwidth";
	};

	dmc_monitor {
		compatible = "amlogic, dmc_monitor";
		status = "okay";
		reg_base = <0xff639000>;
		interrupts = <0x0 0x33 0x1>;
	};

	defendkey {
		compatible = "amlogic, defendkey";
		reg = <0x0 0xff630218 0x0 0x4>;
		mem_size = <0x0 0x100000>;
		status = "okay";
		phandle = <0xda>;
	};

	aml_dma {
		compatible = "amlogic,aml_txlx_dma";
		reg = <0x0 0xff63e000 0x0 0x48>;
		interrupts = <0x0 0xb4 0x1>;

		aml_aes {
			compatible = "amlogic,aes_g12a_dma";
			dev_name = "aml_aes_dma";
			status = "okay";
		};

		aml_sha {
			compatible = "amlogic,sha_dma";
			dev_name = "aml_sha_dma";
			status = "okay";
		};

		aml_tdes {
			compatible = "amlogic,tdes_dma";
			dev_name = "aml_tdes_dma";
			status = "okay";
		};
	};

	rng {
		compatible = "amlogic,meson-rng";
		status = "okay";
		#address-cells = <0x2>;
		#size-cells = <0x2>;
		reg = <0x0 0xff630218 0x0 0x4>;
		quality = [03 e8];
	};

	efuse {
		compatible = "amlogic, efuse";
		read_cmd = <0x82000030>;
		write_cmd = <0x82000031>;
		get_max_cmd = <0x82000033>;
		key = <0x4b>;
		clocks = <0x2 0x62>;
		clock-names = "efuse_clk";
		status = "disabled";
		phandle = <0xdb>;
	};

	cpu_ver_name {
		compatible = "amlogic, cpu-major-id-g12a";
	};

	aliases {
		serial0 = "/soc/aobus@ff800000/serial@3000";
		serial1 = "/serial@ffd24000";
		serial2 = "/serial@ffd23000";
		serial3 = "/serial@ffd22000";
		serial4 = "/soc/aobus@ff800000/serial@4000";
		tsensor0 = "/p_tsensor@ff634594";
		tsensor1 = "/d_tsensor@ff800228";
		i2c0 = "/soc/cbus@ffd00000/i2c@1f000";
		i2c1 = "/soc/cbus@ffd00000/i2c@1e000";
		i2c2 = "/soc/cbus@ffd00000/i2c@1d000";
		i2c3 = "/soc/cbus@ffd00000/i2c@1c000";
		i2c4 = "/soc/aobus@ff800000/i2c@5000";
	};

	memory@00000000 {
		device_type = "memory";
		linux,usable-memory = <0x0 0x0 0x0 0x80000000>;
	};

	reserved-memory {
		#address-cells = <0x2>;
		#size-cells = <0x2>;
		ranges;

		ramoops@0x07400000 {
			compatible = "ramoops";
			reg = <0x0 0x7400000 0x0 0x100000>;
			record-size = <0x20000>;
			console-size = <0x40000>;
			ftrace-size = <0x80000>;
			pmsg-size = <0x20000>;
		};

		linux,secmon {
			compatible = "shared-dma-pool";
			reusable;
			size = <0x0 0x400000>;
			alignment = <0x0 0x400000>;
			alloc-ranges = <0x0 0x5000000 0x0 0x400000>;
			phandle = <0xf>;
		};

		linux,secos {
			status = "disable";
			compatible = "amlogic, aml_secos_memory";
			reg = <0x0 0x5300000 0x0 0x2000000>;
			no-map;
			phandle = <0xdc>;
		};

		linux,meson-fb {
			compatible = "shared-dma-pool";
			reusable;
			size = <0x0 0x800000>;
			alignment = <0x0 0x400000>;
			alloc-ranges = <0x0 0x77800000 0x0 0x800000>;
			phandle = <0x31>;
		};

		linux,ion-dev {
			compatible = "shared-dma-pool";
			reusable;
			size = <0x0 0x8000000>;
			alignment = <0x0 0x400000>;
			phandle = <0x1d>;
		};

		linux,ion-fb {
			compatible = "amlogic, ion-fb-mem";
			reusable;
			size = <0x0 0x1c00000>;
			alignment = <0x0 0x400000>;
			phandle = <0x1e>;
		};

		linux,di_cma {
			compatible = "shared-dma-pool";
			reusable;
			size = <0x0 0x0>;
			alignment = <0x0 0x400000>;
			status = "disable";
			phandle = <0x54>;
		};

		linux,ppmgr {
			compatible = "shared-dma-pool";
			size = <0x0 0x0>;
			phandle = <0x53>;
		};

		linux,codec_mm_cma {
			compatible = "shared-dma-pool";
			reusable;
			size = <0x0 0x1b000000>;
			alignment = <0x0 0x400000>;
			linux,contiguous-region;
			phandle = <0x50>;
		};

		linux,codec_mm_reserved {
			compatible = "amlogic, codec-mm-reserved";
			size = <0x0 0x0>;
			alignment = <0x0 0x100000>;
			phandle = <0x51>;
		};

		linux,vdin1_cma {
			compatible = "shared-dma-pool";
			reusable;
			size = <0x0 0x1400000>;
			alignment = <0x0 0x400000>;
			status = "disabled";
			phandle = <0x30>;
		};

		linux,vdin0_cma {
			status = "disabled";
		};

		linux,isp_cma {
			status = "disabled";
		};

		linux,adapt_cma {
			status = "disabled";
		};
	};

	cma_shrinker {
		compatible = "amlogic, cma-shrinker";
		status = "okay";
		adj = <0x0 0x64 0xc8 0xfa 0x384 0x3b6>;
		free = <0x2000 0x3000 0x4000 0x6000 0x7000 0x8000>;
	};

	dummy-battery {
		compatible = "amlogic, dummy-battery";
		status = "disabled";
		phandle = <0xdd>;
	};

	dummy-charger {
		compatible = "amlogic, dummy-charger";
		status = "disabled";
		phandle = <0xde>;
	};

	gpioleds {
		compatible = "gpio-leds";
		status = "okay";

		sys_led {
			label = "sys_led";
			gpios = <0x4c 0xb 0x0>;
			linux,default-trigger = "default-on";
		};

		net_led {
			label = "net_led";
			gpios = <0x4c 0x9 0x0>;
			default-state = "off";
			linux,default-trigger = "sdio";
		};

		remote_led {
			label = "remote_led";
			gpios = <0x4c 0xa 0x1>;
			default-state = "off";
			linux,default-trigger = "rc-feedback";
		};
	};

	cvbsout {
		compatible = "amlogic, cvbsout-g12a";
		dev_name = "cvbsout";
		status = "okay";
		clocks = <0x2 0x56 0x2 0x4f 0x2 0x50 0x2 0x58>;
		clock-names = "venci_top_gate", "venci_0_gate", "venci_1_gate", "vdac_clk_gate";
		clk_path = <0x0>;
		performance = <0x1bf0 0x9 0x1b56 0x333 0x1b12 0x8080 0x1b05 0xfd 0x1c59 0xf850 0xffff 0x0>;
		performance_sarft = <0x1bf0 0x9 0x1b56 0x333 0x1b12 0x0 0x1b05 0x9 0x1c59 0xfc48 0xffff 0x0>;
		performance_revB_telecom = <0x1bf0 0x9 0x1b56 0x546 0x1b12 0x8080 0x1b05 0x9 0x1c59 0xf850 0xffff 0x0>;
	};

	bt-dev {
		compatible = "amlogic, bt-dev";
		dev_name = "bt-dev";
		status = "okay";
		gpio_reset = <0x28 0x53 0x0>;
		gpio_hostwake = <0x28 0x55 0x0>;
	};

	wifi {
		compatible = "amlogic, aml_wifi";
		dev_name = "aml_wifi";
		status = "okay";
		interrupt_pin = <0x28 0x49 0x0>;
		irq_trigger_type = "GPIO_IRQ_LOW";
		power_on_pin = <0x28 0x48 0x0>;
		dhd_static_buf;
		pinctrl-names = "default";
		pinctrl-0 = <0x4d>;
		pwm_config = <0x4e>;
	};

	wifi_pwm_conf {
		phandle = <0x4e>;

		pwm_channel1_conf {
			pwms = <0x4f 0x0 0x774d 0x0>;
			duty-cycle = <0x3ba6>;
			times = <0xa>;
		};

		pwm_channel2_conf {
			pwms = <0x4f 0x2 0x7724 0x0>;
			duty-cycle = <0x3b92>;
			times = <0xc>;
		};
	};

	linux,picdec {
		compatible = "shared-dma-pool";
		reusable;
		size = <0x0>;
		alignment = <0x0>;
		linux,contiguous-region;
		phandle = <0x52>;
	};

	codec_mm {
		compatible = "amlogic, codec, mm";
		memory-region = <0x50 0x51>;
		dev_name = "codec_mm";
		status = "okay";
		clear-map;
	};

	picdec {
		compatible = "amlogic, picdec";
		memory-region = <0x52>;
		dev_name = "picdec";
		status = "okay";
	};

	ppmgr {
		compatible = "amlogic, ppmgr";
		memory-region = <0x53>;
		dev_name = "ppmgr";
		status = "okay";
	};

	deinterlace {
		compatible = "amlogic, deinterlace";
		status = "disable";
		flag_cma = <0x1>;
		memory-region = <0x54>;
		interrupts = <0x0 0x2e 0x1 0x0 0x28 0x1>;
		interrupt-names = "pre_irq", "post_irq";
		clocks = <0x2 0x9c 0x2 0x9d>;
		clock-names = "vpu_clkb_tmp_composite", "vpu_clkb_composite";
		clock-range = <0x14e 0x29b>;
		buffer-size = <0x3e2c40>;
		post-wr-support = <0x1>;
		nr10bit-support = <0x1>;
		nrds-enable = <0x1>;
		pps-enable = <0x1>;
	};

	ionvideo {
		compatible = "amlogic, ionvideo";
		dev_name = "ionvideo";
		status = "okay";
	};

	provisionkey {
		compatible = "amlogic, provisionkey";
		status = "okay";
		key-permit-default = "write";

		KEY_PROVISION_XXX {
		};
	};

	unifykey {
		compatible = "amlogic, unifykey";
		status = "ok";
		unifykey-num = <0x10>;
		unifykey-index-0 = <0x55>;
		unifykey-index-1 = <0x56>;
		unifykey-index-2 = <0x57>;
		unifykey-index-3 = <0x58>;
		unifykey-index-4 = <0x59>;
		unifykey-index-5 = <0x5a>;
		unifykey-index-6 = <0x5b>;
		unifykey-index-7 = <0x5c>;
		unifykey-index-8 = <0x5d>;
		unifykey-index-9 = <0x5e>;
		unifykey-index-10 = <0x5f>;
		unifykey-index-11 = <0x60>;
		unifykey-index-12 = <0x61>;
		unifykey-index-13 = <0x62>;
		unifykey-index-14 = <0x63>;
		unifykey-index-15 = <0x64>;

		key_0 {
			key-name = "usid";
			key-device = "normal";
			key-permit = "read", "write", "del";
			phandle = <0x55>;
		};

		key_1 {
			key-name = "mac";
			key-device = "normal";
			key-permit = "read", "write", "del";
			phandle = <0x56>;
		};

		key_2 {
			key-name = "hdcp";
			key-device = "secure";
			key-type = "sha1";
			key-permit = "read", "write", "del";
			phandle = <0x57>;
		};

		key_3 {
			key-name = "secure_boot_set";
			key-device = "efuse";
			key-permit = "write";
			phandle = <0x58>;
		};

		key_4 {
			key-name = "mac_bt";
			key-device = "normal";
			key-permit = "read", "write", "del";
			key-type = "mac";
			phandle = <0x59>;
		};

		key_5 {
			key-name = "mac_wifi";
			key-device = "normal";
			key-permit = "read", "write", "del";
			key-type = "mac";
			phandle = <0x5a>;
		};

		key_6 {
			key-name = "hdcp2_tx";
			key-device = "normal";
			key-permit = "read", "write", "del";
			phandle = <0x5b>;
		};

		key_7 {
			key-name = "hdcp2_rx";
			key-device = "normal";
			key-permit = "read", "write", "del";
			phandle = <0x5c>;
		};

		key_8 {
			key-name = "widevinekeybox";
			key-device = "secure";
			key-permit = "read", "write", "del";
			phandle = <0x5d>;
		};

		key_9 {
			key-name = "deviceid";
			key-device = "normal";
			key-permit = "read", "write", "del";
			phandle = <0x5e>;
		};

		key_10 {
			key-name = "hdcp22_fw_private";
			key-device = "secure";
			key-permit = "read", "write", "del";
			phandle = <0x5f>;
		};

		key_11 {
			key-name = "PlayReadykeybox25";
			key-device = "secure";
			key-permit = "read", "write", "del";
			phandle = <0x60>;
		};

		key_12 {
			key-name = "prpubkeybox";
			key-device = "secure";
			key-permit = "read", "write", "del";
			phandle = <0x61>;
		};

		key_13 {
			key-name = "prprivkeybox";
			key-device = "secure";
			key-permit = "read", "write", "del";
			phandle = <0x62>;
		};

		key_14 {
			key-name = "attestationkeybox";
			key-device = "secure";
			key-permit = "read", "write", "del";
			phandle = <0x63>;
		};

		key_15 {
			key-name = "netflix_mgkid";
			key-device = "secure";
			key-permit = "read", "write", "del";
			phandle = <0x64>;
		};
	};

	efusekey {
		keynum = <0x4>;
		key0 = <0x65>;
		key1 = <0x66>;
		key2 = <0x67>;
		key3 = <0x68>;
		phandle = <0x4b>;

		key_0 {
			keyname = "mac";
			offset = <0x0>;
			size = <0x6>;
			phandle = <0x65>;
		};

		key_1 {
			keyname = "mac_bt";
			offset = <0x6>;
			size = <0x6>;
			phandle = <0x66>;
		};

		key_2 {
			keyname = "mac_wifi";
			offset = <0xc>;
			size = <0x6>;
			phandle = <0x67>;
		};

		key_3 {
			keyname = "usid";
			offset = <0x12>;
			size = <0x10>;
			phandle = <0x68>;
		};
	};

	amlvecm {
		compatible = "amlogic, vecm";
		dev_name = "aml_vecm";
		status = "okay";
		gamma_en = <0x0>;
		wb_en = <0x0>;
		cm_en = <0x0>;
		tx_op_color_primary = <0x0>;
	};

	amdolby_vision {
		compatible = "amlogic, dolby_vision_g12a";
		dev_name = "aml_amdolby_vision_driver";
		status = "okay";
		tv_mode = <0x0>;
	};

	dummy {
		#sound-dai-cells = <0x0>;
		compatible = "amlogic, aml_dummy_codec";
		status = "okay";
		phandle = <0x6b>;
	};

	t9015 {
		#sound-dai-cells = <0x0>;
		compatible = "amlogic, aml_codec_T9015";
		reg = <0x0 0xff632000 0x0 0x2000>;
		is_auge_used = <0x1>;
		tdmout_index = <0x1>;
		status = "okay";
		phandle = <0x6d>;
	};

	eqdrc {
		eqdrc_module = <0x1>;
		lane_mask = <0x1>;
		channel_mask = <0x3>;
		phandle = <0x69>;
	};

	auge_sound {
		compatible = "amlogic, g12a-sound-card";
		aml-audio-card,name = "AML-AUGESOUND";
		avout_mute-gpios = <0x4c 0x2 0x0>;
		aml-audio-card,effect = <0x69>;

		aml-audio-card,dai-link@0 {
			mclk-fs = <0x80>;
			continuous-clock;

			cpu {
				sound-dai = <0x6a>;
				system-clock-frequency = <0x5dc000>;
				phandle = <0xdf>;
			};

			codec {
				sound-dai = <0x6b>;
				phandle = <0xe0>;
			};
		};

		aml-audio-card,dai-link@1 {
			format = "i2s";
			mclk-fs = <0x100>;
			bitclock-master = <0x6c>;
			frame-master = <0x6c>;
			continuous-clock;

			cpu {
				sound-dai = <0x6c>;
				dai-tdm-slot-tx-mask = <0x1 0x1>;
				dai-tdm-slot-rx-mask = <0x1 0x1>;
				dai-tdm-slot-num = <0x2>;
				dai-tdm-slot-width = <0x20>;
				system-clock-frequency = <0xbb8000>;
			};

			codec {
				sound-dai = <0x6d>;
				phandle = <0xe1>;
			};
		};

		aml-audio-card,dai-link@2 {
			mclk-fs = <0x80>;
			continuous-clock;

			cpu {
				sound-dai = <0x6e>;
				system-clock-frequency = <0x5dc000>;
			};

			codec {
				sound-dai = <0x6b>;
			};
		};

		aml-audio-card,dai-link@3 {
			mclk-fs = <0x100>;
			format = "i2s";
			bitclock-master = <0x6f>;
			frame-master = <0x6f>;
			continuous-clock;

			cpu {
				sound-dai = <0x6f>;
				dai-tdm-slot-tx-mask = <0x1 0x1>;
				dai-tdm-slot-rx-mask = <0x1 0x1>;
				dai-tdm-slot-num = <0x2>;
				dai-tdm-slot-width = <0x20>;
				system-clock-frequency = <0xbb8000>;
			};

			codec {
				sound-dai = <0x6b>;
			};
		};
	};

	locker {
		compatible = "amlogic, audiolocker";
		clocks = <0x1f 0x22 0x1f 0x23 0x1f 0x1a 0x1f 0x1b 0x2 0xd 0x2 0xe>;
		clock-names = "lock_out", "lock_in", "out_src", "in_src", "out_calc", "in_ref";
		interrupts = <0x0 0x1 0x1>;
		interrupt-names = "irq";
		frequency = <0x2ebae40>;
		dividor = <0x31>;
		status = "okay";
		phandle = <0xe2>;
	};

	cpu_opp_table0 {
		compatible = "operating-points-v2";
		opp-shared;
		phandle = <0xd>;

		opp00 {
			opp-hz = <0x0 0x5f5e100>;
			opp-microvolt = <0xb2778>;
		};

		opp01 {
			opp-hz = <0x0 0xee6b280>;
			opp-microvolt = <0xb2778>;
		};

		opp02 {
			opp-hz = <0x0 0x1dcd6500>;
			opp-microvolt = <0xb2778>;
		};

		opp03 {
			opp-hz = <0x0 0x27c19cc0>;
			opp-microvolt = <0xb2778>;
		};

		opp04 {
			opp-hz = <0x0 0x3b9aca00>;
			opp-microvolt = <0xb2778>;
		};

		opp05 {
			opp-hz = <0x0 0x47868c00>;
			opp-microvolt = <0xb9ca8>;
		};

		opp06 {
			opp-hz = <0x0 0x5353c980>;
			opp-microvolt = <0xc11d8>;
		};

		opp07 {
			opp-hz = <0x0 0x5a1f4a00>;
			opp-microvolt = <0xcae18>;
		};

		opp08 {
			opp-hz = <0x0 0x5fd82200>;
			opp-microvolt = <0xd4a58>;
		};

		opp09 {
			opp-hz = <0x0 0x6590fa00>;
			opp-microvolt = <0xe0da8>;
		};

		opp10 {
			opp-hz = <0x0 0x6b49d200>;
			opp-microvolt = <0xef808>;
		};
	};

	cpufreq-meson {
		compatible = "amlogic, cpufreq-meson";
		pinctrl-names = "default";
		pinctrl-0 = <0x70>;
		status = "okay";
	};

	chosen {
	};

	gpio_keypad {
		reg = <0x0 0xff800000 0x0 0x400>;
	};

	meson-ir {
		compatible = "amlogic,meson6-ir";
		reg = <0x0 0xff808040 0x0 0x44>;
		interrupts = <0x0 0xc4 0x1>;
		pinctrl-names = "default";
		pinctrl-0 = <0x71>;
		pulse-inverted;
		wakeup_protocol = <0x9>;
		status = "okay";
	};

	meson-remote {
		compatible = "amlogic, aml_remote";
		dev_name = "meson-remote";
		reg = <0x0 0xff808040 0x0 0x44 0x0 0xff808000 0x0 0x20>;
		status = "okay";
		protocol = <0x1>;
		led_blink = <0x1>;
		led_blink_frq = <0x64>;
		interrupts = <0x0 0xc4 0x1>;
		pinctrl-names = "default";
		pinctrl-0 = <0x71>;
		max_frame_time = <0xc8>;
	};

	amvideocap {
		compatible = "amlogic, amvideocap";
		dev_name = "amvideocap.0";
		status = "okay";
		max_size = <0x8>;
	};

	openvfd {
		compatible = "open,vfd";
		dev_name = "openvfd";
		status = "okay";
	};

	multi-di {
		compatible = "amlogic, dim-g12a";
		status = "okay";
		flag_cma = <0x4>;
		memory-region = <0x54>;
		interrupts = <0x0 0x2e 0x1 0x0 0x28 0x1>;
		interrupt-names = "pre_irq", "post_irq";
		clocks = <0x2 0x9c 0x2 0x9d>;
		clock-names = "vpu_clkb_tmp_composite", "vpu_clkb_composite";
		clock-range = <0x14e 0x29b>;
		buffer-size = <0x3e2c40>;
		post-wr-support = <0x1>;
		nr10bit-support = <0x1>;
		nrds-enable = <0x1>;
		pps-enable = <0x1>;
	};

	__symbols__ {
		gpu = "/bifrost";
		dvfs125_cfg = "/bifrost/clk125_cfg";
		dvfs250_cfg = "/bifrost/dvfs250_cfg";
		dvfs285_cfg = "/bifrost/dvfs285_cfg";
		dvfs400_cfg = "/bifrost/dvfs400_cfg";
		dvfs500_cfg = "/bifrost/dvfs500_cfg";
		dvfs666_cfg = "/bifrost/dvfs666_cfg";
		dvfs800_cfg = "/bifrost/dvfs800_cfg";
		dvfs850_cfg = "/bifrost/dvfs850_cfg";
		cpus = "/cpus";
		cluster0 = "/cpus/cpu-map/cluster0";
		CPU0 = "/cpus/cpu@0";
		CPU1 = "/cpus/cpu@1";
		CPU2 = "/cpus/cpu@2";
		CPU3 = "/cpus/cpu@3";
		CPU_SLEEP_0 = "/cpus/idle-states/cpu-sleep-0";
		gic = "/interrupt-controller@2c001000";
		mailbox = "/mhu@c883c400";
		xtal = "/xtal-clk";
		ethmac = "/ethernet@ff3f0000";
		pinctrl_aobus = "/pinctrl@ff800014";
		gpio_ao = "/pinctrl@ff800014/ao-bank@ff800014";
		sd_to_ao_uart_clr_pins = "/pinctrl@ff800014/sd_to_ao_uart_clr_pins";
		sd_to_ao_uart_pins = "/pinctrl@ff800014/sd_to_ao_uart_pins";
		ao_uart_pins = "/pinctrl@ff800014/ao_uart";
		ao_b_uart_pins = "/pinctrl@ff800014/ao_b_uart";
		ao_i2c_master_pins1 = "/pinctrl@ff800014/ao_i2c_pins1";
		ao_i2c_master_pins2 = "/pinctrl@ff800014/ao_i2c_pins2";
		ao_i2c_slave_pins = "/pinctrl@ff800014/ao_i2c_slave_pins";
		pwm_ao_a_pins = "/pinctrl@ff800014/pwm_ao_a";
		pwm_ao_a_hiz_pins = "/pinctrl@ff800014/pwm_ao_a_hiz";
		pwm_ao_b_pins = "/pinctrl@ff800014/pwm_ao_b";
		pwm_ao_c_pins1 = "/pinctrl@ff800014/pwm_ao_c_pins1";
		pwm_ao_c_pins2 = "/pinctrl@ff800014/pwm_ao_c_pins2";
		pwm_ao_c_hiz_pins = "/pinctrl@ff800014/pwm_ao_c_hiz";
		pwm_ao_d_pins1 = "/pinctrl@ff800014/pwm_ao_d_pins1";
		pwm_ao_d_pins2 = "/pinctrl@ff800014/pwm_ao_d_pins2";
		pwm_ao_d_pins3 = "/pinctrl@ff800014/pwm_ao_d_pins3";
		aocec_a = "/pinctrl@ff800014/ao_ceca";
		aocec_b = "/pinctrl@ff800014/ao_cecb";
		jtag_apao_pins = "/pinctrl@ff800014/jtag_apao_pin";
		remote_pins = "/pinctrl@ff800014/remote_pin";
		irblaster_pins = "/pinctrl@ff800014/irblaster_pin";
		pinctrl_periphs = "/pinctrl@ff634480";
		gpio = "/pinctrl@ff634480/banks@ff6346c0";
		emmc_clk_cmd_pins = "/pinctrl@ff634480/emmc_clk_cmd_pins";
		emmc_conf_pull_up = "/pinctrl@ff634480/emmc_conf_pull_up";
		emmc_conf_pull_done = "/pinctrl@ff634480/emmc_conf_pull_done";
		sd_clk_cmd_pins = "/pinctrl@ff634480/sd_clk_cmd_pins";
		sd_all_pins = "/pinctrl@ff634480/sd_all_pins";
		sd_1bit_pins = "/pinctrl@ff634480/sd_1bit_pins";
		sd_clr_all_pins = "/pinctrl@ff634480/sd_clr_all_pins";
		sd_clr_noall_pins = "/pinctrl@ff634480/sd_clr_noall_pins";
		ao_to_sd_uart_pins = "/pinctrl@ff634480/ao_to_sd_uart_pins";
		sdio_clk_cmd_pins = "/pinctrl@ff634480/sdio_clk_cmd_pins";
		sdio_all_pins = "/pinctrl@ff634480/sdio_all_pins";
		sdio_x_clk_cmd_pins = "/pinctrl@ff634480/sdio_x_clk_cmd_pins";
		sdio_x_all_pins = "/pinctrl@ff634480/sdio_x_all_pins";
		sdio_x_en_pins = "/pinctrl@ff634480/sdio_x_en_pins";
		sdio_x_clr_pins = "/pinctrl@ff634480/sdio_x_clr_pins";
		all_nand_pins = "/pinctrl@ff634480/all_nand_pins";
		nand_cs_pins = "/pinctrl@ff634480/nand_cs";
		i2c0_master_pins1 = "/pinctrl@ff634480/i2c0_pins1";
		i2c0_master_pins2 = "/pinctrl@ff634480/i2c0_pins2";
		i2c0_master_pins3 = "/pinctrl@ff634480/i2c0_pins3";
		i2c1_master_pins1 = "/pinctrl@ff634480/i2c1_pins1";
		i2c1_master_pins2 = "/pinctrl@ff634480/i2c1_pins2";
		i2c1_master_pins3 = "/pinctrl@ff634480/i2c1_pins3";
		i2c2_master_pins1 = "/pinctrl@ff634480/i2c2_pins1";
		i2c2_master_pins2 = "/pinctrl@ff634480/i2c2_pins2";
		i2c3_master_pins1 = "/pinctrl@ff634480/i2c3_pins1";
		i2c3_master_pins2 = "/pinctrl@ff634480/i2c3_pins2";
		pwm_a_pins = "/pinctrl@ff634480/pwm_a";
		pwm_b_pins1 = "/pinctrl@ff634480/pwm_b_pins1";
		pwm_b_pins2 = "/pinctrl@ff634480/pwm_b_pins2";
		pwm_c_pins1 = "/pinctrl@ff634480/pwm_c_pins1";
		pwm_c_pins2 = "/pinctrl@ff634480/pwm_c_pins2";
		pwm_c_pins3 = "/pinctrl@ff634480/pwm_c_pins3";
		pwm_d_pins1 = "/pinctrl@ff634480/pwm_d_pins1";
		pwm_d_pins2 = "/pinctrl@ff634480/pwm_d_pins2";
		pwm_e_pins = "/pinctrl@ff634480/pwm_e";
		pwm_f_pins1 = "/pinctrl@ff634480/pwm_f_pins1";
		pwm_f_pins2 = "/pinctrl@ff634480/pwm_f_pins2";
		spicc0_pins_x = "/pinctrl@ff634480/spicc0_pins_x";
		spicc0_pins_c = "/pinctrl@ff634480/spicc0_pins_c";
		spicc1_pins = "/pinctrl@ff634480/spicc1_pins";
		a_uart_pins = "/pinctrl@ff634480/a_uart";
		b_uart_pins = "/pinctrl@ff634480/b_uart";
		c_uart_pins = "/pinctrl@ff634480/c_uart";
		hdmitx_hpd = "/pinctrl@ff634480/hdmitx_hpd";
		hdmitx_hpd_gpio = "/pinctrl@ff634480/hdmitx_hpd_gpio";
		hdmitx_ddc = "/pinctrl@ff634480/hdmitx_ddc";
		eecec_a = "/pinctrl@ff634480/ee_ceca";
		eecec_b = "/pinctrl@ff634480/ee_cecb";
		internal_eth_pins = "/pinctrl@ff634480/internal_eth_pins";
		internal_gpio_pins = "/pinctrl@ff634480/internal_gpio_pins";
		external_eth_pins = "/pinctrl@ff634480/external_eth_pins";
		jtag_apee_pins = "/pinctrl@ff634480/jtag_apee_pin";
		tdmb_mclk = "/pinctrl@ff634480/tdmb_mclk";
		tdmout_b = "/pinctrl@ff634480/tdmout_b";
		tdmin_b = "/pinctrl@ff634480/tdmin_b";
		spdifout = "/pinctrl@ff634480/spdifout";
		spdifout_a_mute = "/pinctrl@ff634480/spdifout_a_mute";
		audio_data = "/audio_data";
		dwc3 = "/dwc3@ff500000";
		usb2_phy_v2 = "/usb2phy@ffe09000";
		usb3_phy_v2 = "/usb3phy@ffe09080";
		dwc2_a = "/dwc2_a@ff400000";
		wdt = "/watchdog@0xffd0f0d0";
		saradc = "/saradc";
		p_tsensor = "/p_tsensor@ff634594";
		d_tsensor = "/d_tsensor@ff800228";
		bl40 = "/bl40";
		cbus = "/soc/cbus@ffd00000";
		gpio_intc = "/soc/cbus@ffd00000/interrupt-controller@f080";
		pwm_ab = "/soc/cbus@ffd00000/pwm@1b000";
		pwm_cd = "/soc/cbus@ffd00000/pwm@1a000";
		pwm_ef = "/soc/cbus@ffd00000/pwm@19000";
		i2c0 = "/soc/cbus@ffd00000/i2c@1f000";
		i2c1 = "/soc/cbus@ffd00000/i2c@1e000";
		i2c2 = "/soc/cbus@ffd00000/i2c@1d000";
		i2c3 = "/soc/cbus@ffd00000/i2c@1c000";
		spicc0 = "/soc/cbus@ffd00000/spi@13000";
		spicc1 = "/soc/cbus@ffd00000/spi@15000";
		aobus = "/soc/aobus@ff800000";
		aoclkc = "/soc/aobus@ff800000/clock-controller@0";
		pwm_AO_ab = "/soc/aobus@ff800000/pwm@7000";
		pwm_AO_cd = "/soc/aobus@ff800000/pwm@2000";
		i2c_AO = "/soc/aobus@ff800000/i2c@5000";
		i2c_AO_slave = "/soc/aobus@ff800000/i2c_slave@6000";
		uart_AO = "/soc/aobus@ff800000/serial@3000";
		uart_AO_B = "/soc/aobus@ff800000/serial@4000";
		irblaster = "/soc/aobus@ff800000/meson-irblaster@14c";
		periphs = "/soc/periphs@ff634400";
		hiubus = "/soc/hiubus@ff63c000";
		clkc = "/soc/hiubus@ff63c000/clock-controller@0";
		audiobus = "/soc/audiobus@0xff642000";
		clkaudio = "/soc/audiobus@0xff642000/audio_clocks";
		aml_tdmb = "/soc/audiobus@0xff642000/tdmb";
		aml_i2s2hdmi = "/soc/audiobus@0xff642000/i2s2hdmi";
		aml_spdif = "/soc/audiobus@0xff642000/spdif";
		aml_spdif_b = "/soc/audiobus@0xff642000/spdif_b";
		loopback = "/soc/audiobus@0xff642000/loopback@0";
		audioresample = "/soc/audiobus@0xff642000/resample";
		aml_pwrdet = "/soc/audiobus@0xff642000/pwrdet";
		uart_A = "/serial@ffd24000";
		uart_B = "/serial@ffd23000";
		uart_C = "/serial@ffd22000";
		pcie_A = "/pcieA@fc000000";
		amhdmitx = "/amhdmitx";
		vend_data = "/amhdmitx/vend_data";
		amprime_sl = "/amprime_sl";
		aocec = "/aocec";
		vdin0 = "/vdin0";
		vdin1 = "/vdin1";
		vout_sys = "/vout_sys";
		dummy_venc = "/dummy_venc";
		canvas = "/canvas";
		codec_io = "/codec_io";
		meson_fb = "/meson-fb";
		sd_emmc_c = "/emmc@ffe07000";
		sd_emmc_b1 = "/sd1@ffe05000";
		sd_emmc_b2 = "/sd2@ffe05000";
		sd_emmc_b3 = "/sd3@ffe05000";
		sd_emmc_a = "/sdio@ffe03000";
		meson_cooldev = "/meson-cooldev@0";
		cpufreq_cool0 = "/meson-cooldev@0/cpufreq_cool0";
		cpucore_cool0 = "/meson-cooldev@0/cpucore_cool0";
		gpufreq_cool0 = "/meson-cooldev@0/gpufreq_cool0";
		gpucore_cool0 = "/meson-cooldev@0/gpucore_cool0";
		soc_thermal = "/thermal-zones/soc_thermal";
		pswitch_on = "/thermal-zones/soc_thermal/trips/trip-point@0";
		pcontrol = "/thermal-zones/soc_thermal/trips/trip-point@1";
		phot = "/thermal-zones/soc_thermal/trips/trip-point@2";
		pcritical = "/thermal-zones/soc_thermal/trips/trip-point@3";
		ddr_thermal = "/thermal-zones/ddr_thermal";
		dswitch_on = "/thermal-zones/ddr_thermal/trips/trip-point@0";
		dcontrol = "/thermal-zones/ddr_thermal/trips/trip-point@1";
		dhot = "/thermal-zones/ddr_thermal/trips/trip-point@2";
		dcritical = "/thermal-zones/ddr_thermal/trips/trip-point@3";
		vddcpu0 = "/pwmao_d-regulator";
		defendkey = "/defendkey";
		efuse = "/efuse";
		secmon_reserved = "/reserved-memory/linux,secmon";
		secos_reserved = "/reserved-memory/linux,secos";
		logo_reserved = "/reserved-memory/linux,meson-fb";
		ion_cma_reserved = "/reserved-memory/linux,ion-dev";
		ion_fb_reserved = "/reserved-memory/linux,ion-fb";
		di_cma_reserved = "/reserved-memory/linux,di_cma";
		ppmgr_reserved = "/reserved-memory/linux,ppmgr";
		codec_mm_cma = "/reserved-memory/linux,codec_mm_cma";
		codec_mm_reserved = "/reserved-memory/linux,codec_mm_reserved";
		vdin1_cma_reserved = "/reserved-memory/linux,vdin1_cma";
		amlogic_battery = "/dummy-battery";
		amlogic_charger = "/dummy-charger";
		wifi_pwm_conf = "/wifi_pwm_conf";
		picdec_cma_reserved = "/linux,picdec";
		keysn_0 = "/unifykey/key_0";
		keysn_1 = "/unifykey/key_1";
		keysn_2 = "/unifykey/key_2";
		keysn_3 = "/unifykey/key_3";
		keysn_4 = "/unifykey/key_4";
		keysn_5 = "/unifykey/key_5";
		keysn_6 = "/unifykey/key_6";
		keysn_7 = "/unifykey/key_7";
		keysn_8 = "/unifykey/key_8";
		keysn_9 = "/unifykey/key_9";
		keysn_10 = "/unifykey/key_10";
		keysn_11 = "/unifykey/key_11";
		keysn_12 = "/unifykey/key_12";
		keysn_13 = "/unifykey/key_13";
		keysn_14 = "/unifykey/key_14";
		keysn_15 = "/unifykey/key_15";
		efusekey = "/efusekey";
		key_0 = "/efusekey/key_0";
		key_1 = "/efusekey/key_1";
		key_2 = "/efusekey/key_2";
		key_3 = "/efusekey/key_3";
		dummy_codec = "/dummy";
		pdm_codec = "/dummy";
		amlogic_codec = "/t9015";
		audio_effect = "/eqdrc";
		audiolocker = "/locker";
		cpu_opp_table0 = "/cpu_opp_table0";
	};
};
